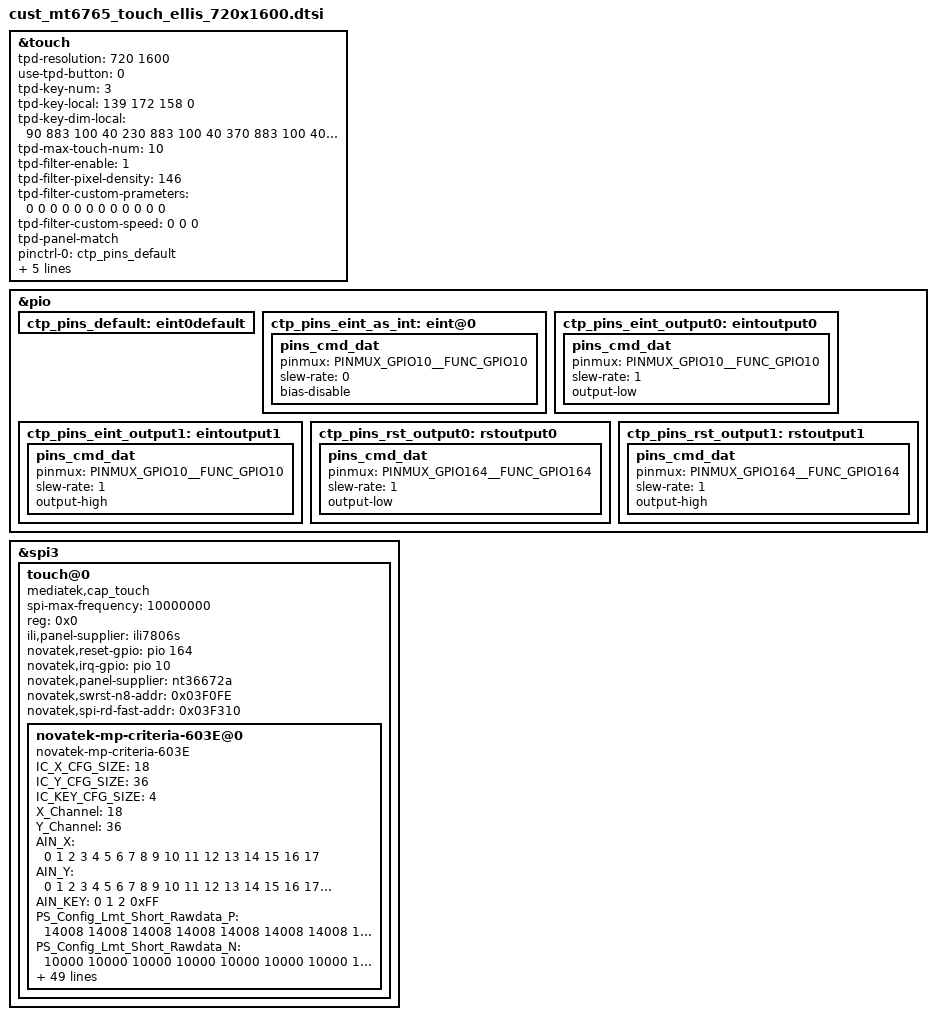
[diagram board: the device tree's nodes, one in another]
// SPDX-License-Identifier: GPL-2.0+
/*
 * Copyright (c) 2019 MediaTek Inc.
 *
 */

/* TOUCH start */
&touch {
	tpd-resolution = <720 1600>;
	use-tpd-button = <0>;
	tpd-key-num = <3>;
	tpd-key-local= <139 172 158 0>;
	tpd-key-dim-local = <90 883 100 40 230
				 883 100 40 370 883 100 40 0 0 0 0>;
	tpd-max-touch-num = <10>;
	tpd-filter-enable = <1>;
	tpd-filter-pixel-density = <146>;
	tpd-filter-custom-prameters = <0 0 0 0 0 0 0 0 0 0 0 0>;
	tpd-filter-custom-speed = <0 0 0>;
	tpd-panel-match;
	pinctrl-names = "default", "state_eint_as_int", "state_eint_output0",
		"state_eint_output1", "state_rst_output0", "state_rst_output1";
	pinctrl-0 = <&ctp_pins_default>;
	pinctrl-1 = <&ctp_pins_eint_as_int>;
	pinctrl-2 = <&ctp_pins_eint_output0>;
	pinctrl-3 = <&ctp_pins_eint_output1>;
	pinctrl-4 = <&ctp_pins_rst_output0>;
	pinctrl-5 = <&ctp_pins_rst_output1>;
	status = "okay";
};
&pio {
	ctp_pins_default: eint0default {
	};
	ctp_pins_eint_as_int: eint@0 {
		pins_cmd_dat {
			pinmux = <PINMUX_GPIO10__FUNC_GPIO10>;
			slew-rate = <0>;
			bias-disable;
		};
	};
	ctp_pins_eint_output0: eintoutput0 {
		pins_cmd_dat {
			pinmux = <PINMUX_GPIO10__FUNC_GPIO10>;
			slew-rate = <1>;
			output-low;
		};
	};
	ctp_pins_eint_output1: eintoutput1 {
		pins_cmd_dat {
			pinmux = <PINMUX_GPIO10__FUNC_GPIO10>;
			slew-rate = <1>;
			output-high;
		};
	};
	ctp_pins_rst_output0: rstoutput0 {
		pins_cmd_dat {
			pinmux = <PINMUX_GPIO164__FUNC_GPIO164>;
			slew-rate = <1>;
			output-low;
		};
	};
	ctp_pins_rst_output1: rstoutput1 {
		pins_cmd_dat {
			pinmux = <PINMUX_GPIO164__FUNC_GPIO164>;
			slew-rate = <1>;
			output-high;
		};
	};
};
/* TOUCH end */

&spi3 {
	#address-cells = <1>;
	#size-cells = <0>;

	touch@0{
		compatible = "mediatek,cap_touch","novatek,NVT-ts-spi";
 		spi-max-frequency = <10000000>;
		reg = <0x0>;
		status = "okay";

		ili,panel-supplier = "ili7806s";

		novatek,reset-gpio = <&pio 164 0>;
		novatek,irq-gpio = <&pio 10 2008>;
		novatek,panel-supplier = "nt36672a";

		//novatek,pen-support;
		//novatek,wgp-stylus;

		/* 525 */
		//novatek,swrst-n8-addr = <0x01F01A>;

		/* 672A, 525B, 675, 526, 672C, 523 */
		novatek,swrst-n8-addr = <0x03F0FE>;
		novatek,spi-rd-fast-addr = <0x03F310>;

		/* MP */
		//novatek,mp-support-dt;

		novatek-mp-criteria-603E@0 {
			#address-cells = <1>;
			#size-cells = <0>;
			compatible = "novatek-mp-criteria-603E";

			/* MP Config */
			IC_X_CFG_SIZE = <18>;
			IC_Y_CFG_SIZE = <36>;
			IC_KEY_CFG_SIZE = <4>;
			X_Channel = <18>;
			Y_Channel = <36>;
			AIN_X = <0 1 2 3 4 5 6 7 8 9 10 11 12 13 14 15 16 17>;
			AIN_Y = <0 1 2 3 4 5 6 7 8 9 10 11 12 13 14 15 16 17 18 19 20 21 22 23 24 25 26 27 28 29 30 31 32 33 34 35>;
			//AIN_X = <0 1 2 3 4 5 6 7 8 9 10 11 12 13 14 15 16 17 18 19 20 21 22 23 24 25 26 27 28 29 30 31>;
			//AIN_Y = <0 1 2 3 4 5 6 7 8 9 10 11 12 13 14 15 16 17 18 19 20 21 22 23 24 25 26 27 28 29 30 31 32 33 34 35 36 37 38 39 40 41 42 43 44 45 46 47 48 49>;
			AIN_KEY = <0 1 2 0xFF>;

			/* MP Criteria */
			PS_Config_Lmt_Short_Rawdata_P = <
				14008 14008 14008 14008 14008 14008 14008 14008 14008 14008 14008 14008 14008 14008 14008 14008 14008 14008 14008 14008 14008 14008 14008 14008 14008 14008 14008 14008 14008 14008 14008 14008
				14008 14008 14008 14008 14008 14008 14008 14008 14008 14008 14008 14008 14008 14008 14008 14008 14008 14008 14008 14008 14008 14008 14008 14008 14008 14008 14008 14008 14008 14008 14008 14008
				14008 14008 14008 14008 14008 14008 14008 14008 14008 14008 14008 14008 14008 14008 14008 14008 14008 14008 14008 14008 14008 14008 14008 14008 14008 14008 14008 14008 14008 14008 14008 14008
				14008 14008 14008 14008 14008 14008 14008 14008 14008 14008 14008 14008 14008 14008 14008 14008 14008 14008 14008 14008 14008 14008 14008 14008 14008 14008 14008 14008 14008 14008 14008 14008
				14008 14008 14008 14008 14008 14008 14008 14008 14008 14008 14008 14008 14008 14008 14008 14008 14008 14008 14008 14008 14008 14008 14008 14008 14008 14008 14008 14008 14008 14008 14008 14008
				14008 14008 14008 14008 14008 14008 14008 14008 14008 14008 14008 14008 14008 14008 14008 14008 14008 14008 14008 14008 14008 14008 14008 14008 14008 14008 14008 14008 14008 14008 14008 14008
				14008 14008 14008 14008 14008 14008 14008 14008 14008 14008 14008 14008 14008 14008 14008 14008 14008 14008 14008 14008 14008 14008 14008 14008 14008 14008 14008 14008 14008 14008 14008 14008
				14008 14008 14008 14008 14008 14008 14008 14008 14008 14008 14008 14008 14008 14008 14008 14008 14008 14008 14008 14008 14008 14008 14008 14008 14008 14008 14008 14008 14008 14008 14008 14008
				14008 14008 14008 14008 14008 14008 14008 14008 14008 14008 14008 14008 14008 14008 14008 14008 14008 14008 14008 14008 14008 14008 14008 14008 14008 14008 14008 14008 14008 14008 14008 14008
				14008 14008 14008 14008 14008 14008 14008 14008 14008 14008 14008 14008 14008 14008 14008 14008 14008 14008 14008 14008 14008 14008 14008 14008 14008 14008 14008 14008 14008 14008 14008 14008
				14008 14008 14008 14008 14008 14008 14008 14008 14008 14008 14008 14008 14008 14008 14008 14008 14008 14008 14008 14008 14008 14008 14008 14008 14008 14008 14008 14008 14008 14008 14008 14008
				14008 14008 14008 14008 14008 14008 14008 14008 14008 14008 14008 14008 14008 14008 14008 14008 14008 14008 14008 14008 14008 14008 14008 14008 14008 14008 14008 14008 14008 14008 14008 14008
				14008 14008 14008 14008 14008 14008 14008 14008 14008 14008 14008 14008 14008 14008 14008 14008 14008 14008 14008 14008 14008 14008 14008 14008 14008 14008 14008 14008 14008 14008 14008 14008
				14008 14008 14008 14008 14008 14008 14008 14008 14008 14008 14008 14008 14008 14008 14008 14008 14008 14008 14008 14008 14008 14008 14008 14008 14008 14008 14008 14008 14008 14008 14008 14008
				14008 14008 14008 14008 14008 14008 14008 14008 14008 14008 14008 14008 14008 14008 14008 14008 14008 14008 14008 14008 14008 14008 14008 14008 14008 14008 14008 14008 14008 14008 14008 14008
				14008 14008 14008 14008 14008 14008 14008 14008 14008 14008 14008 14008 14008 14008 14008 14008 14008 14008 14008 14008 14008 14008 14008 14008 14008 14008 14008 14008 14008 14008 14008 14008
				14008 14008 14008 14008 14008 14008 14008 14008 14008 14008 14008 14008 14008 14008 14008 14008 14008 14008 14008 14008 14008 14008 14008 14008 14008 14008 14008 14008 14008 14008 14008 14008
				14008 14008 14008 14008 14008 14008 14008 14008 14008 14008 14008 14008 14008 14008 14008 14008 14008 14008 14008 14008 14008 14008 14008 14008 14008 14008 14008 14008 14008 14008 14008 14008
				14008 14008 14008 14008 14008 14008 14008 14008 14008 14008 14008 14008 14008 14008 14008 14008 14008 14008 14008 14008 14008 14008 14008 14008 14008 14008 14008 14008 14008 14008 14008 14008
				14008 14008 14008 14008 14008 14008 14008 14008 14008 14008 14008 14008 14008 14008 14008 14008 14008 14008 14008 14008 14008 14008 14008 14008 14008 14008 14008 14008 14008 14008 14008 14008
				14008 14008 14008 14008 14008 14008 14008 14008 14008 14008 14008 14008 14008 14008 14008 14008 14008 14008 14008 14008 14008 14008 14008 14008 14008 14008 14008 14008 14008 14008 14008 14008
				14008 14008 14008 14008 14008 14008 14008 14008 14008 14008 14008 14008 14008 14008 14008 14008 14008 14008 14008 14008 14008 14008 14008 14008 14008 14008 14008 14008 14008 14008 14008 14008
				14008 14008 14008 14008 14008 14008 14008 14008 14008 14008 14008 14008 14008 14008 14008 14008 14008 14008 14008 14008 14008 14008 14008 14008 14008 14008 14008 14008 14008 14008 14008 14008
				14008 14008 14008 14008 14008 14008 14008 14008 14008 14008 14008 14008 14008 14008 14008 14008 14008 14008 14008 14008 14008 14008 14008 14008 14008 14008 14008 14008 14008 14008 14008 14008
				14008 14008 14008 14008 14008 14008 14008 14008 14008 14008 14008 14008 14008 14008 14008 14008 14008 14008 14008 14008 14008 14008 14008 14008 14008 14008 14008 14008 14008 14008 14008 14008
				14008 14008 14008 14008 14008 14008 14008 14008 14008 14008 14008 14008 14008 14008 14008 14008 14008 14008 14008 14008 14008 14008 14008 14008 14008 14008 14008 14008 14008 14008 14008 14008
				14008 14008 14008 14008 14008 14008 14008 14008 14008 14008 14008 14008 14008 14008 14008 14008 14008 14008 14008 14008 14008 14008 14008 14008 14008 14008 14008 14008 14008 14008 14008 14008
				14008 14008 14008 14008 14008 14008 14008 14008 14008 14008 14008 14008 14008 14008 14008 14008 14008 14008 14008 14008 14008 14008 14008 14008 14008 14008 14008 14008 14008 14008 14008 14008
				14008 14008 14008 14008 14008 14008 14008 14008 14008 14008 14008 14008 14008 14008 14008 14008 14008 14008 14008 14008 14008 14008 14008 14008 14008 14008 14008 14008 14008 14008 14008 14008
				14008 14008 14008 14008 14008 14008 14008 14008 14008 14008 14008 14008 14008 14008 14008 14008 14008 14008 14008 14008 14008 14008 14008 14008 14008 14008 14008 14008 14008 14008 14008 14008
				14008 14008 14008 14008 14008 14008 14008 14008 14008 14008 14008 14008 14008 14008 14008 14008 14008 14008 14008 14008 14008 14008 14008 14008 14008 14008 14008 14008 14008 14008 14008 14008
				14008 14008 14008 14008 14008 14008 14008 14008 14008 14008 14008 14008 14008 14008 14008 14008 14008 14008 14008 14008 14008 14008 14008 14008 14008 14008 14008 14008 14008 14008 14008 14008
				14008 14008 14008 14008 14008 14008 14008 14008 14008 14008 14008 14008 14008 14008 14008 14008 14008 14008 14008 14008 14008 14008 14008 14008 14008 14008 14008 14008 14008 14008 14008 14008
				14008 14008 14008 14008 14008 14008 14008 14008 14008 14008 14008 14008 14008 14008 14008 14008 14008 14008 14008 14008 14008 14008 14008 14008 14008 14008 14008 14008 14008 14008 14008 14008
				14008 14008 14008 14008 14008 14008 14008 14008 14008 14008 14008 14008 14008 14008 14008 14008 14008 14008 14008 14008 14008 14008 14008 14008 14008 14008 14008 14008 14008 14008 14008 14008
				14008 14008 14008 14008 14008 14008 14008 14008 14008 14008 14008 14008 14008 14008 14008 14008 14008 14008 14008 14008 14008 14008 14008 14008 14008 14008 14008 14008 14008 14008 14008 14008
				14008 14008 14008 14008 14008 14008 14008 14008 14008 14008 14008 14008 14008 14008 14008 14008 14008 14008 14008 14008 14008 14008 14008 14008 14008 14008 14008 14008 14008 14008 14008 14008
				14008 14008 14008 14008 14008 14008 14008 14008 14008 14008 14008 14008 14008 14008 14008 14008 14008 14008 14008 14008 14008 14008 14008 14008 14008 14008 14008 14008 14008 14008 14008 14008
				14008 14008 14008 14008 14008 14008 14008 14008 14008 14008 14008 14008 14008 14008 14008 14008 14008 14008 14008 14008 14008 14008 14008 14008 14008 14008 14008 14008 14008 14008 14008 14008
				14008 14008 14008 14008 14008 14008 14008 14008 14008 14008 14008 14008 14008 14008 14008 14008 14008 14008 14008 14008 14008 14008 14008 14008 14008 14008 14008 14008 14008 14008 14008 14008
				14008 14008 14008 14008 14008 14008 14008 14008 14008 14008 14008 14008 14008 14008 14008 14008 14008 14008 14008 14008 14008 14008 14008 14008 14008 14008 14008 14008 14008 14008 14008 14008
				14008 14008 14008 14008 14008 14008 14008 14008 14008 14008 14008 14008 14008 14008 14008 14008 14008 14008 14008 14008 14008 14008 14008 14008 14008 14008 14008 14008 14008 14008 14008 14008
				14008 14008 14008 14008 14008 14008 14008 14008 14008 14008 14008 14008 14008 14008 14008 14008 14008 14008 14008 14008 14008 14008 14008 14008 14008 14008 14008 14008 14008 14008 14008 14008
				14008 14008 14008 14008 14008 14008 14008 14008 14008 14008 14008 14008 14008 14008 14008 14008 14008 14008 14008 14008 14008 14008 14008 14008 14008 14008 14008 14008 14008 14008 14008 14008
				14008 14008 14008 14008 14008 14008 14008 14008 14008 14008 14008 14008 14008 14008 14008 14008 14008 14008 14008 14008 14008 14008 14008 14008 14008 14008 14008 14008 14008 14008 14008 14008
				14008 14008 14008 14008 14008 14008 14008 14008 14008 14008 14008 14008 14008 14008 14008 14008 14008 14008 14008 14008 14008 14008 14008 14008 14008 14008 14008 14008 14008 14008 14008 14008
				14008 14008 14008 14008 14008 14008 14008 14008 14008 14008 14008 14008 14008 14008 14008 14008 14008 14008 14008 14008 14008 14008 14008 14008 14008 14008 14008 14008 14008 14008 14008 14008
				14008 14008 14008 14008 14008 14008 14008 14008 14008 14008 14008 14008 14008 14008 14008 14008 14008 14008 14008 14008 14008 14008 14008 14008 14008 14008 14008 14008 14008 14008 14008 14008
				14008 14008 14008 14008 14008 14008 14008 14008 14008 14008 14008 14008 14008 14008 14008 14008 14008 14008 14008 14008 14008 14008 14008 14008 14008 14008 14008 14008 14008 14008 14008 14008
				14008 14008 14008 14008 14008 14008 14008 14008 14008 14008 14008 14008 14008 14008 14008 14008 14008 14008 14008 14008 14008 14008 14008 14008 14008 14008 14008 14008 14008 14008 14008 14008
				14008 14008 14008>;

			PS_Config_Lmt_Short_Rawdata_N = <
				10000 10000 10000 10000 10000 10000 10000 10000 10000 10000 10000 10000 10000 10000 10000 10000 10000 10000 10000 10000 10000 10000 10000 10000 10000 10000 10000 10000 10000 10000 10000 10000
				10000 10000 10000 10000 10000 10000 10000 10000 10000 10000 10000 10000 10000 10000 10000 10000 10000 10000 10000 10000 10000 10000 10000 10000 10000 10000 10000 10000 10000 10000 10000 10000
				10000 10000 10000 10000 10000 10000 10000 10000 10000 10000 10000 10000 10000 10000 10000 10000 10000 10000 10000 10000 10000 10000 10000 10000 10000 10000 10000 10000 10000 10000 10000 10000
				10000 10000 10000 10000 10000 10000 10000 10000 10000 10000 10000 10000 10000 10000 10000 10000 10000 10000 10000 10000 10000 10000 10000 10000 10000 10000 10000 10000 10000 10000 10000 10000
				10000 10000 10000 10000 10000 10000 10000 10000 10000 10000 10000 10000 10000 10000 10000 10000 10000 10000 10000 10000 10000 10000 10000 10000 10000 10000 10000 10000 10000 10000 10000 10000
				10000 10000 10000 10000 10000 10000 10000 10000 10000 10000 10000 10000 10000 10000 10000 10000 10000 10000 10000 10000 10000 10000 10000 10000 10000 10000 10000 10000 10000 10000 10000 10000
				10000 10000 10000 10000 10000 10000 10000 10000 10000 10000 10000 10000 10000 10000 10000 10000 10000 10000 10000 10000 10000 10000 10000 10000 10000 10000 10000 10000 10000 10000 10000 10000
				10000 10000 10000 10000 10000 10000 10000 10000 10000 10000 10000 10000 10000 10000 10000 10000 10000 10000 10000 10000 10000 10000 10000 10000 10000 10000 10000 10000 10000 10000 10000 10000
				10000 10000 10000 10000 10000 10000 10000 10000 10000 10000 10000 10000 10000 10000 10000 10000 10000 10000 10000 10000 10000 10000 10000 10000 10000 10000 10000 10000 10000 10000 10000 10000
				10000 10000 10000 10000 10000 10000 10000 10000 10000 10000 10000 10000 10000 10000 10000 10000 10000 10000 10000 10000 10000 10000 10000 10000 10000 10000 10000 10000 10000 10000 10000 10000
				10000 10000 10000 10000 10000 10000 10000 10000 10000 10000 10000 10000 10000 10000 10000 10000 10000 10000 10000 10000 10000 10000 10000 10000 10000 10000 10000 10000 10000 10000 10000 10000
				10000 10000 10000 10000 10000 10000 10000 10000 10000 10000 10000 10000 10000 10000 10000 10000 10000 10000 10000 10000 10000 10000 10000 10000 10000 10000 10000 10000 10000 10000 10000 10000
				10000 10000 10000 10000 10000 10000 10000 10000 10000 10000 10000 10000 10000 10000 10000 10000 10000 10000 10000 10000 10000 10000 10000 10000 10000 10000 10000 10000 10000 10000 10000 10000
				10000 10000 10000 10000 10000 10000 10000 10000 10000 10000 10000 10000 10000 10000 10000 10000 10000 10000 10000 10000 10000 10000 10000 10000 10000 10000 10000 10000 10000 10000 10000 10000
				10000 10000 10000 10000 10000 10000 10000 10000 10000 10000 10000 10000 10000 10000 10000 10000 10000 10000 10000 10000 10000 10000 10000 10000 10000 10000 10000 10000 10000 10000 10000 10000
				10000 10000 10000 10000 10000 10000 10000 10000 10000 10000 10000 10000 10000 10000 10000 10000 10000 10000 10000 10000 10000 10000 10000 10000 10000 10000 10000 10000 10000 10000 10000 10000
				10000 10000 10000 10000 10000 10000 10000 10000 10000 10000 10000 10000 10000 10000 10000 10000 10000 10000 10000 10000 10000 10000 10000 10000 10000 10000 10000 10000 10000 10000 10000 10000
				10000 10000 10000 10000 10000 10000 10000 10000 10000 10000 10000 10000 10000 10000 10000 10000 10000 10000 10000 10000 10000 10000 10000 10000 10000 10000 10000 10000 10000 10000 10000 10000
				10000 10000 10000 10000 10000 10000 10000 10000 10000 10000 10000 10000 10000 10000 10000 10000 10000 10000 10000 10000 10000 10000 10000 10000 10000 10000 10000 10000 10000 10000 10000 10000
				10000 10000 10000 10000 10000 10000 10000 10000 10000 10000 10000 10000 10000 10000 10000 10000 10000 10000 10000 10000 10000 10000 10000 10000 10000 10000 10000 10000 10000 10000 10000 10000
				10000 10000 10000 10000 10000 10000 10000 10000 10000 10000 10000 10000 10000 10000 10000 10000 10000 10000 10000 10000 10000 10000 10000 10000 10000 10000 10000 10000 10000 10000 10000 10000
				10000 10000 10000 10000 10000 10000 10000 10000 10000 10000 10000 10000 10000 10000 10000 10000 10000 10000 10000 10000 10000 10000 10000 10000 10000 10000 10000 10000 10000 10000 10000 10000
				10000 10000 10000 10000 10000 10000 10000 10000 10000 10000 10000 10000 10000 10000 10000 10000 10000 10000 10000 10000 10000 10000 10000 10000 10000 10000 10000 10000 10000 10000 10000 10000
				10000 10000 10000 10000 10000 10000 10000 10000 10000 10000 10000 10000 10000 10000 10000 10000 10000 10000 10000 10000 10000 10000 10000 10000 10000 10000 10000 10000 10000 10000 10000 10000
				10000 10000 10000 10000 10000 10000 10000 10000 10000 10000 10000 10000 10000 10000 10000 10000 10000 10000 10000 10000 10000 10000 10000 10000 10000 10000 10000 10000 10000 10000 10000 10000
				10000 10000 10000 10000 10000 10000 10000 10000 10000 10000 10000 10000 10000 10000 10000 10000 10000 10000 10000 10000 10000 10000 10000 10000 10000 10000 10000 10000 10000 10000 10000 10000
				10000 10000 10000 10000 10000 10000 10000 10000 10000 10000 10000 10000 10000 10000 10000 10000 10000 10000 10000 10000 10000 10000 10000 10000 10000 10000 10000 10000 10000 10000 10000 10000
				10000 10000 10000 10000 10000 10000 10000 10000 10000 10000 10000 10000 10000 10000 10000 10000 10000 10000 10000 10000 10000 10000 10000 10000 10000 10000 10000 10000 10000 10000 10000 10000
				10000 10000 10000 10000 10000 10000 10000 10000 10000 10000 10000 10000 10000 10000 10000 10000 10000 10000 10000 10000 10000 10000 10000 10000 10000 10000 10000 10000 10000 10000 10000 10000
				10000 10000 10000 10000 10000 10000 10000 10000 10000 10000 10000 10000 10000 10000 10000 10000 10000 10000 10000 10000 10000 10000 10000 10000 10000 10000 10000 10000 10000 10000 10000 10000
				10000 10000 10000 10000 10000 10000 10000 10000 10000 10000 10000 10000 10000 10000 10000 10000 10000 10000 10000 10000 10000 10000 10000 10000 10000 10000 10000 10000 10000 10000 10000 10000
				10000 10000 10000 10000 10000 10000 10000 10000 10000 10000 10000 10000 10000 10000 10000 10000 10000 10000 10000 10000 10000 10000 10000 10000 10000 10000 10000 10000 10000 10000 10000 10000
				10000 10000 10000 10000 10000 10000 10000 10000 10000 10000 10000 10000 10000 10000 10000 10000 10000 10000 10000 10000 10000 10000 10000 10000 10000 10000 10000 10000 10000 10000 10000 10000
				10000 10000 10000 10000 10000 10000 10000 10000 10000 10000 10000 10000 10000 10000 10000 10000 10000 10000 10000 10000 10000 10000 10000 10000 10000 10000 10000 10000 10000 10000 10000 10000
				10000 10000 10000 10000 10000 10000 10000 10000 10000 10000 10000 10000 10000 10000 10000 10000 10000 10000 10000 10000 10000 10000 10000 10000 10000 10000 10000 10000 10000 10000 10000 10000
				10000 10000 10000 10000 10000 10000 10000 10000 10000 10000 10000 10000 10000 10000 10000 10000 10000 10000 10000 10000 10000 10000 10000 10000 10000 10000 10000 10000 10000 10000 10000 10000
				10000 10000 10000 10000 10000 10000 10000 10000 10000 10000 10000 10000 10000 10000 10000 10000 10000 10000 10000 10000 10000 10000 10000 10000 10000 10000 10000 10000 10000 10000 10000 10000
				10000 10000 10000 10000 10000 10000 10000 10000 10000 10000 10000 10000 10000 10000 10000 10000 10000 10000 10000 10000 10000 10000 10000 10000 10000 10000 10000 10000 10000 10000 10000 10000
				10000 10000 10000 10000 10000 10000 10000 10000 10000 10000 10000 10000 10000 10000 10000 10000 10000 10000 10000 10000 10000 10000 10000 10000 10000 10000 10000 10000 10000 10000 10000 10000
				10000 10000 10000 10000 10000 10000 10000 10000 10000 10000 10000 10000 10000 10000 10000 10000 10000 10000 10000 10000 10000 10000 10000 10000 10000 10000 10000 10000 10000 10000 10000 10000
				10000 10000 10000 10000 10000 10000 10000 10000 10000 10000 10000 10000 10000 10000 10000 10000 10000 10000 10000 10000 10000 10000 10000 10000 10000 10000 10000 10000 10000 10000 10000 10000
				10000 10000 10000 10000 10000 10000 10000 10000 10000 10000 10000 10000 10000 10000 10000 10000 10000 10000 10000 10000 10000 10000 10000 10000 10000 10000 10000 10000 10000 10000 10000 10000
				10000 10000 10000 10000 10000 10000 10000 10000 10000 10000 10000 10000 10000 10000 10000 10000 10000 10000 10000 10000 10000 10000 10000 10000 10000 10000 10000 10000 10000 10000 10000 10000
				10000 10000 10000 10000 10000 10000 10000 10000 10000 10000 10000 10000 10000 10000 10000 10000 10000 10000 10000 10000 10000 10000 10000 10000 10000 10000 10000 10000 10000 10000 10000 10000
				10000 10000 10000 10000 10000 10000 10000 10000 10000 10000 10000 10000 10000 10000 10000 10000 10000 10000 10000 10000 10000 10000 10000 10000 10000 10000 10000 10000 10000 10000 10000 10000
				10000 10000 10000 10000 10000 10000 10000 10000 10000 10000 10000 10000 10000 10000 10000 10000 10000 10000 10000 10000 10000 10000 10000 10000 10000 10000 10000 10000 10000 10000 10000 10000
				10000 10000 10000 10000 10000 10000 10000 10000 10000 10000 10000 10000 10000 10000 10000 10000 10000 10000 10000 10000 10000 10000 10000 10000 10000 10000 10000 10000 10000 10000 10000 10000
				10000 10000 10000 10000 10000 10000 10000 10000 10000 10000 10000 10000 10000 10000 10000 10000 10000 10000 10000 10000 10000 10000 10000 10000 10000 10000 10000 10000 10000 10000 10000 10000
				10000 10000 10000 10000 10000 10000 10000 10000 10000 10000 10000 10000 10000 10000 10000 10000 10000 10000 10000 10000 10000 10000 10000 10000 10000 10000 10000 10000 10000 10000 10000 10000
				10000 10000 10000 10000 10000 10000 10000 10000 10000 10000 10000 10000 10000 10000 10000 10000 10000 10000 10000 10000 10000 10000 10000 10000 10000 10000 10000 10000 10000 10000 10000 10000
				10000 10000 10000>;

			PS_Config_Lmt_Open_Rawdata_P = <
				5120 5120 5120 5120 5120 5120 5120 5120 5120 5120 5120 5120 5120 5120 5120 5120 5120 5120 5120 5120 5120 5120 5120 5120 5120 5120 5120 5120 5120 5120 5120 5120
				5120 5120 5120 5120 5120 5120 5120 5120 5120 5120 5120 5120 5120 5120 5120 5120 5120 5120 5120 5120 5120 5120 5120 5120 5120 5120 5120 5120 5120 5120 5120 5120
				5120 5120 5120 5120 5120 5120 5120 5120 5120 5120 5120 5120 5120 5120 5120 5120 5120 5120 5120 5120 5120 5120 5120 5120 5120 5120 5120 5120 5120 5120 5120 5120
				5120 5120 5120 5120 5120 5120 5120 5120 5120 5120 5120 5120 5120 5120 5120 5120 5120 5120 5120 5120 5120 5120 5120 5120 5120 5120 5120 5120 5120 5120 5120 5120
				5120 5120 5120 5120 5120 5120 5120 5120 5120 5120 5120 5120 5120 5120 5120 5120 5120 5120 5120 5120 5120 5120 5120 5120 5120 5120 5120 5120 5120 5120 5120 5120
				5120 5120 5120 5120 5120 5120 5120 5120 5120 5120 5120 5120 5120 5120 5120 5120 5120 5120 5120 5120 5120 5120 5120 5120 5120 5120 5120 5120 5120 5120 5120 5120
				5120 5120 5120 5120 5120 5120 5120 5120 5120 5120 5120 5120 5120 5120 5120 5120 5120 5120 5120 5120 5120 5120 5120 5120 5120 5120 5120 5120 5120 5120 5120 5120
				5120 5120 5120 5120 5120 5120 5120 5120 5120 5120 5120 5120 5120 5120 5120 5120 5120 5120 5120 5120 5120 5120 5120 5120 5120 5120 5120 5120 5120 5120 5120 5120
				5120 5120 5120 5120 5120 5120 5120 5120 5120 5120 5120 5120 5120 5120 5120 5120 5120 5120 5120 5120 5120 5120 5120 5120 5120 5120 5120 5120 5120 5120 5120 5120
				5120 5120 5120 5120 5120 5120 5120 5120 5120 5120 5120 5120 5120 5120 5120 5120 5120 5120 5120 5120 5120 5120 5120 5120 5120 5120 5120 5120 5120 5120 5120 5120
				5120 5120 5120 5120 5120 5120 5120 5120 5120 5120 5120 5120 5120 5120 5120 5120 5120 5120 5120 5120 5120 5120 5120 5120 5120 5120 5120 5120 5120 5120 5120 5120
				5120 5120 5120 5120 5120 5120 5120 5120 5120 5120 5120 5120 5120 5120 5120 5120 5120 5120 5120 5120 5120 5120 5120 5120 5120 5120 5120 5120 5120 5120 5120 5120
				5120 5120 5120 5120 5120 5120 5120 5120 5120 5120 5120 5120 5120 5120 5120 5120 5120 5120 5120 5120 5120 5120 5120 5120 5120 5120 5120 5120 5120 5120 5120 5120
				5120 5120 5120 5120 5120 5120 5120 5120 5120 5120 5120 5120 5120 5120 5120 5120 5120 5120 5120 5120 5120 5120 5120 5120 5120 5120 5120 5120 5120 5120 5120 5120
				5120 5120 5120 5120 5120 5120 5120 5120 5120 5120 5120 5120 5120 5120 5120 5120 5120 5120 5120 5120 5120 5120 5120 5120 5120 5120 5120 5120 5120 5120 5120 5120
				5120 5120 5120 5120 5120 5120 5120 5120 5120 5120 5120 5120 5120 5120 5120 5120 5120 5120 5120 5120 5120 5120 5120 5120 5120 5120 5120 5120 5120 5120 5120 5120
				5120 5120 5120 5120 5120 5120 5120 5120 5120 5120 5120 5120 5120 5120 5120 5120 5120 5120 5120 5120 5120 5120 5120 5120 5120 5120 5120 5120 5120 5120 5120 5120
				5120 5120 5120 5120 5120 5120 5120 5120 5120 5120 5120 5120 5120 5120 5120 5120 5120 5120 5120 5120 5120 5120 5120 5120 5120 5120 5120 5120 5120 5120 5120 5120
				5120 5120 5120 5120 5120 5120 5120 5120 5120 5120 5120 5120 5120 5120 5120 5120 5120 5120 5120 5120 5120 5120 5120 5120 5120 5120 5120 5120 5120 5120 5120 5120
				5120 5120 5120 5120 5120 5120 5120 5120 5120 5120 5120 5120 5120 5120 5120 5120 5120 5120 5120 5120 5120 5120 5120 5120 5120 5120 5120 5120 5120 5120 5120 5120
				5120 5120 5120 5120 5120 5120 5120 5120 5120 5120 5120 5120 5120 5120 5120 5120 5120 5120 5120 5120 5120 5120 5120 5120 5120 5120 5120 5120 5120 5120 5120 5120
				5120 5120 5120 5120 5120 5120 5120 5120 5120 5120 5120 5120 5120 5120 5120 5120 5120 5120 5120 5120 5120 5120 5120 5120 5120 5120 5120 5120 5120 5120 5120 5120
				5120 5120 5120 5120 5120 5120 5120 5120 5120 5120 5120 5120 5120 5120 5120 5120 5120 5120 5120 5120 5120 5120 5120 5120 5120 5120 5120 5120 5120 5120 5120 5120
				5120 5120 5120 5120 5120 5120 5120 5120 5120 5120 5120 5120 5120 5120 5120 5120 5120 5120 5120 5120 5120 5120 5120 5120 5120 5120 5120 5120 5120 5120 5120 5120
				5120 5120 5120 5120 5120 5120 5120 5120 5120 5120 5120 5120 5120 5120 5120 5120 5120 5120 5120 5120 5120 5120 5120 5120 5120 5120 5120 5120 5120 5120 5120 5120
				5120 5120 5120 5120 5120 5120 5120 5120 5120 5120 5120 5120 5120 5120 5120 5120 5120 5120 5120 5120 5120 5120 5120 5120 5120 5120 5120 5120 5120 5120 5120 5120
				5120 5120 5120 5120 5120 5120 5120 5120 5120 5120 5120 5120 5120 5120 5120 5120 5120 5120 5120 5120 5120 5120 5120 5120 5120 5120 5120 5120 5120 5120 5120 5120
				5120 5120 5120 5120 5120 5120 5120 5120 5120 5120 5120 5120 5120 5120 5120 5120 5120 5120 5120 5120 5120 5120 5120 5120 5120 5120 5120 5120 5120 5120 5120 5120
				5120 5120 5120 5120 5120 5120 5120 5120 5120 5120 5120 5120 5120 5120 5120 5120 5120 5120 5120 5120 5120 5120 5120 5120 5120 5120 5120 5120 5120 5120 5120 5120
				5120 5120 5120 5120 5120 5120 5120 5120 5120 5120 5120 5120 5120 5120 5120 5120 5120 5120 5120 5120 5120 5120 5120 5120 5120 5120 5120 5120 5120 5120 5120 5120
				5120 5120 5120 5120 5120 5120 5120 5120 5120 5120 5120 5120 5120 5120 5120 5120 5120 5120 5120 5120 5120 5120 5120 5120 5120 5120 5120 5120 5120 5120 5120 5120
				5120 5120 5120 5120 5120 5120 5120 5120 5120 5120 5120 5120 5120 5120 5120 5120 5120 5120 5120 5120 5120 5120 5120 5120 5120 5120 5120 5120 5120 5120 5120 5120
				5120 5120 5120 5120 5120 5120 5120 5120 5120 5120 5120 5120 5120 5120 5120 5120 5120 5120 5120 5120 5120 5120 5120 5120 5120 5120 5120 5120 5120 5120 5120 5120
				5120 5120 5120 5120 5120 5120 5120 5120 5120 5120 5120 5120 5120 5120 5120 5120 5120 5120 5120 5120 5120 5120 5120 5120 5120 5120 5120 5120 5120 5120 5120 5120
				5120 5120 5120 5120 5120 5120 5120 5120 5120 5120 5120 5120 5120 5120 5120 5120 5120 5120 5120 5120 5120 5120 5120 5120 5120 5120 5120 5120 5120 5120 5120 5120
				5120 5120 5120 5120 5120 5120 5120 5120 5120 5120 5120 5120 5120 5120 5120 5120 5120 5120 5120 5120 5120 5120 5120 5120 5120 5120 5120 5120 5120 5120 5120 5120
				5120 5120 5120 5120 5120 5120 5120 5120 5120 5120 5120 5120 5120 5120 5120 5120 5120 5120 5120 5120 5120 5120 5120 5120 5120 5120 5120 5120 5120 5120 5120 5120
				5120 5120 5120 5120 5120 5120 5120 5120 5120 5120 5120 5120 5120 5120 5120 5120 5120 5120 5120 5120 5120 5120 5120 5120 5120 5120 5120 5120 5120 5120 5120 5120
				5120 5120 5120 5120 5120 5120 5120 5120 5120 5120 5120 5120 5120 5120 5120 5120 5120 5120 5120 5120 5120 5120 5120 5120 5120 5120 5120 5120 5120 5120 5120 5120
				5120 5120 5120 5120 5120 5120 5120 5120 5120 5120 5120 5120 5120 5120 5120 5120 5120 5120 5120 5120 5120 5120 5120 5120 5120 5120 5120 5120 5120 5120 5120 5120
				5120 5120 5120 5120 5120 5120 5120 5120 5120 5120 5120 5120 5120 5120 5120 5120 5120 5120 5120 5120 5120 5120 5120 5120 5120 5120 5120 5120 5120 5120 5120 5120
				5120 5120 5120 5120 5120 5120 5120 5120 5120 5120 5120 5120 5120 5120 5120 5120 5120 5120 5120 5120 5120 5120 5120 5120 5120 5120 5120 5120 5120 5120 5120 5120
				5120 5120 5120 5120 5120 5120 5120 5120 5120 5120 5120 5120 5120 5120 5120 5120 5120 5120 5120 5120 5120 5120 5120 5120 5120 5120 5120 5120 5120 5120 5120 5120
				5120 5120 5120 5120 5120 5120 5120 5120 5120 5120 5120 5120 5120 5120 5120 5120 5120 5120 5120 5120 5120 5120 5120 5120 5120 5120 5120 5120 5120 5120 5120 5120
				5120 5120 5120 5120 5120 5120 5120 5120 5120 5120 5120 5120 5120 5120 5120 5120 5120 5120 5120 5120 5120 5120 5120 5120 5120 5120 5120 5120 5120 5120 5120 5120
				5120 5120 5120 5120 5120 5120 5120 5120 5120 5120 5120 5120 5120 5120 5120 5120 5120 5120 5120 5120 5120 5120 5120 5120 5120 5120 5120 5120 5120 5120 5120 5120
				5120 5120 5120 5120 5120 5120 5120 5120 5120 5120 5120 5120 5120 5120 5120 5120 5120 5120 5120 5120 5120 5120 5120 5120 5120 5120 5120 5120 5120 5120 5120 5120
				5120 5120 5120 5120 5120 5120 5120 5120 5120 5120 5120 5120 5120 5120 5120 5120 5120 5120 5120 5120 5120 5120 5120 5120 5120 5120 5120 5120 5120 5120 5120 5120
				5120 5120 5120 5120 5120 5120 5120 5120 5120 5120 5120 5120 5120 5120 5120 5120 5120 5120 5120 5120 5120 5120 5120 5120 5120 5120 5120 5120 5120 5120 5120 5120
				5120 5120 5120 5120 5120 5120 5120 5120 5120 5120 5120 5120 5120 5120 5120 5120 5120 5120 5120 5120 5120 5120 5120 5120 5120 5120 5120 5120 5120 5120 5120 5120
				5120 5120 5120>;

			PS_Config_Lmt_Open_Rawdata_N = <
				(-511) (-511) (-511) (-511) (-511) (-511) (-511) (-511) (-511) (-511) (-511) (-511) (-511) (-511) (-511) (-511) (-511) (-511) (-511) (-511) (-511) (-511) (-511) (-511) (-511) (-511) (-511) (-511) (-511) (-511) (-511) (-511)
				(-511) (-511) (-511) (-511) (-511) (-511) (-511) (-511) (-511) (-511) (-511) (-511) (-511) (-511) (-511) (-511) (-511) (-511) (-511) (-511) (-511) (-511) (-511) (-511) (-511) (-511) (-511) (-511) (-511) (-511) (-511) (-511)
				(-511) (-511) (-511) (-511) (-511) (-511) (-511) (-511) (-511) (-511) (-511) (-511) (-511) (-511) (-511) (-511) (-511) (-511) (-511) (-511) (-511) (-511) (-511) (-511) (-511) (-511) (-511) (-511) (-511) (-511) (-511) (-511)
				(-511) (-511) (-511) (-511) (-511) (-511) (-511) (-511) (-511) (-511) (-511) (-511) (-511) (-511) (-511) (-511) (-511) (-511) (-511) (-511) (-511) (-511) (-511) (-511) (-511) (-511) (-511) (-511) (-511) (-511) (-511) (-511)
				(-511) (-511) (-511) (-511) (-511) (-511) (-511) (-511) (-511) (-511) (-511) (-511) (-511) (-511) (-511) (-511) (-511) (-511) (-511) (-511) (-511) (-511) (-511) (-511) (-511) (-511) (-511) (-511) (-511) (-511) (-511) (-511)
				(-511) (-511) (-511) (-511) (-511) (-511) (-511) (-511) (-511) (-511) (-511) (-511) (-511) (-511) (-511) (-511) (-511) (-511) (-511) (-511) (-511) (-511) (-511) (-511) (-511) (-511) (-511) (-511) (-511) (-511) (-511) (-511)
				(-511) (-511) (-511) (-511) (-511) (-511) (-511) (-511) (-511) (-511) (-511) (-511) (-511) (-511) (-511) (-511) (-511) (-511) (-511) (-511) (-511) (-511) (-511) (-511) (-511) (-511) (-511) (-511) (-511) (-511) (-511) (-511)
				(-511) (-511) (-511) (-511) (-511) (-511) (-511) (-511) (-511) (-511) (-511) (-511) (-511) (-511) (-511) (-511) (-511) (-511) (-511) (-511) (-511) (-511) (-511) (-511) (-511) (-511) (-511) (-511) (-511) (-511) (-511) (-511)
				(-511) (-511) (-511) (-511) (-511) (-511) (-511) (-511) (-511) (-511) (-511) (-511) (-511) (-511) (-511) (-511) (-511) (-511) (-511) (-511) (-511) (-511) (-511) (-511) (-511) (-511) (-511) (-511) (-511) (-511) (-511) (-511)
				(-511) (-511) (-511) (-511) (-511) (-511) (-511) (-511) (-511) (-511) (-511) (-511) (-511) (-511) (-511) (-511) (-511) (-511) (-511) (-511) (-511) (-511) (-511) (-511) (-511) (-511) (-511) (-511) (-511) (-511) (-511) (-511)
				(-511) (-511) (-511) (-511) (-511) (-511) (-511) (-511) (-511) (-511) (-511) (-511) (-511) (-511) (-511) (-511) (-511) (-511) (-511) (-511) (-511) (-511) (-511) (-511) (-511) (-511) (-511) (-511) (-511) (-511) (-511) (-511)
				(-511) (-511) (-511) (-511) (-511) (-511) (-511) (-511) (-511) (-511) (-511) (-511) (-511) (-511) (-511) (-511) (-511) (-511) (-511) (-511) (-511) (-511) (-511) (-511) (-511) (-511) (-511) (-511) (-511) (-511) (-511) (-511)
				(-511) (-511) (-511) (-511) (-511) (-511) (-511) (-511) (-511) (-511) (-511) (-511) (-511) (-511) (-511) (-511) (-511) (-511) (-511) (-511) (-511) (-511) (-511) (-511) (-511) (-511) (-511) (-511) (-511) (-511) (-511) (-511)
				(-511) (-511) (-511) (-511) (-511) (-511) (-511) (-511) (-511) (-511) (-511) (-511) (-511) (-511) (-511) (-511) (-511) (-511) (-511) (-511) (-511) (-511) (-511) (-511) (-511) (-511) (-511) (-511) (-511) (-511) (-511) (-511)
				(-511) (-511) (-511) (-511) (-511) (-511) (-511) (-511) (-511) (-511) (-511) (-511) (-511) (-511) (-511) (-511) (-511) (-511) (-511) (-511) (-511) (-511) (-511) (-511) (-511) (-511) (-511) (-511) (-511) (-511) (-511) (-511)
				(-511) (-511) (-511) (-511) (-511) (-511) (-511) (-511) (-511) (-511) (-511) (-511) (-511) (-511) (-511) (-511) (-511) (-511) (-511) (-511) (-511) (-511) (-511) (-511) (-511) (-511) (-511) (-511) (-511) (-511) (-511) (-511)
				(-511) (-511) (-511) (-511) (-511) (-511) (-511) (-511) (-511) (-511) (-511) (-511) (-511) (-511) (-511) (-511) (-511) (-511) (-511) (-511) (-511) (-511) (-511) (-511) (-511) (-511) (-511) (-511) (-511) (-511) (-511) (-511)
				(-511) (-511) (-511) (-511) (-511) (-511) (-511) (-511) (-511) (-511) (-511) (-511) (-511) (-511) (-511) (-511) (-511) (-511) (-511) (-511) (-511) (-511) (-511) (-511) (-511) (-511) (-511) (-511) (-511) (-511) (-511) (-511)
				(-511) (-511) (-511) (-511) (-511) (-511) (-511) (-511) (-511) (-511) (-511) (-511) (-511) (-511) (-511) (-511) (-511) (-511) (-511) (-511) (-511) (-511) (-511) (-511) (-511) (-511) (-511) (-511) (-511) (-511) (-511) (-511)
				(-511) (-511) (-511) (-511) (-511) (-511) (-511) (-511) (-511) (-511) (-511) (-511) (-511) (-511) (-511) (-511) (-511) (-511) (-511) (-511) (-511) (-511) (-511) (-511) (-511) (-511) (-511) (-511) (-511) (-511) (-511) (-511)
				(-511) (-511) (-511) (-511) (-511) (-511) (-511) (-511) (-511) (-511) (-511) (-511) (-511) (-511) (-511) (-511) (-511) (-511) (-511) (-511) (-511) (-511) (-511) (-511) (-511) (-511) (-511) (-511) (-511) (-511) (-511) (-511)
				(-511) (-511) (-511) (-511) (-511) (-511) (-511) (-511) (-511) (-511) (-511) (-511) (-511) (-511) (-511) (-511) (-511) (-511) (-511) (-511) (-511) (-511) (-511) (-511) (-511) (-511) (-511) (-511) (-511) (-511) (-511) (-511)
				(-511) (-511) (-511) (-511) (-511) (-511) (-511) (-511) (-511) (-511) (-511) (-511) (-511) (-511) (-511) (-511) (-511) (-511) (-511) (-511) (-511) (-511) (-511) (-511) (-511) (-511) (-511) (-511) (-511) (-511) (-511) (-511)
				(-511) (-511) (-511) (-511) (-511) (-511) (-511) (-511) (-511) (-511) (-511) (-511) (-511) (-511) (-511) (-511) (-511) (-511) (-511) (-511) (-511) (-511) (-511) (-511) (-511) (-511) (-511) (-511) (-511) (-511) (-511) (-511)
				(-511) (-511) (-511) (-511) (-511) (-511) (-511) (-511) (-511) (-511) (-511) (-511) (-511) (-511) (-511) (-511) (-511) (-511) (-511) (-511) (-511) (-511) (-511) (-511) (-511) (-511) (-511) (-511) (-511) (-511) (-511) (-511)
				(-511) (-511) (-511) (-511) (-511) (-511) (-511) (-511) (-511) (-511) (-511) (-511) (-511) (-511) (-511) (-511) (-511) (-511) (-511) (-511) (-511) (-511) (-511) (-511) (-511) (-511) (-511) (-511) (-511) (-511) (-511) (-511)
				(-511) (-511) (-511) (-511) (-511) (-511) (-511) (-511) (-511) (-511) (-511) (-511) (-511) (-511) (-511) (-511) (-511) (-511) (-511) (-511) (-511) (-511) (-511) (-511) (-511) (-511) (-511) (-511) (-511) (-511) (-511) (-511)
				(-511) (-511) (-511) (-511) (-511) (-511) (-511) (-511) (-511) (-511) (-511) (-511) (-511) (-511) (-511) (-511) (-511) (-511) (-511) (-511) (-511) (-511) (-511) (-511) (-511) (-511) (-511) (-511) (-511) (-511) (-511) (-511)
				(-511) (-511) (-511) (-511) (-511) (-511) (-511) (-511) (-511) (-511) (-511) (-511) (-511) (-511) (-511) (-511) (-511) (-511) (-511) (-511) (-511) (-511) (-511) (-511) (-511) (-511) (-511) (-511) (-511) (-511) (-511) (-511)
				(-511) (-511) (-511) (-511) (-511) (-511) (-511) (-511) (-511) (-511) (-511) (-511) (-511) (-511) (-511) (-511) (-511) (-511) (-511) (-511) (-511) (-511) (-511) (-511) (-511) (-511) (-511) (-511) (-511) (-511) (-511) (-511)
				(-511) (-511) (-511) (-511) (-511) (-511) (-511) (-511) (-511) (-511) (-511) (-511) (-511) (-511) (-511) (-511) (-511) (-511) (-511) (-511) (-511) (-511) (-511) (-511) (-511) (-511) (-511) (-511) (-511) (-511) (-511) (-511)
				(-511) (-511) (-511) (-511) (-511) (-511) (-511) (-511) (-511) (-511) (-511) (-511) (-511) (-511) (-511) (-511) (-511) (-511) (-511) (-511) (-511) (-511) (-511) (-511) (-511) (-511) (-511) (-511) (-511) (-511) (-511) (-511)
				(-511) (-511) (-511) (-511) (-511) (-511) (-511) (-511) (-511) (-511) (-511) (-511) (-511) (-511) (-511) (-511) (-511) (-511) (-511) (-511) (-511) (-511) (-511) (-511) (-511) (-511) (-511) (-511) (-511) (-511) (-511) (-511)
				(-511) (-511) (-511) (-511) (-511) (-511) (-511) (-511) (-511) (-511) (-511) (-511) (-511) (-511) (-511) (-511) (-511) (-511) (-511) (-511) (-511) (-511) (-511) (-511) (-511) (-511) (-511) (-511) (-511) (-511) (-511) (-511)
				(-511) (-511) (-511) (-511) (-511) (-511) (-511) (-511) (-511) (-511) (-511) (-511) (-511) (-511) (-511) (-511) (-511) (-511) (-511) (-511) (-511) (-511) (-511) (-511) (-511) (-511) (-511) (-511) (-511) (-511) (-511) (-511)
				(-511) (-511) (-511) (-511) (-511) (-511) (-511) (-511) (-511) (-511) (-511) (-511) (-511) (-511) (-511) (-511) (-511) (-511) (-511) (-511) (-511) (-511) (-511) (-511) (-511) (-511) (-511) (-511) (-511) (-511) (-511) (-511)
				(-511) (-511) (-511) (-511) (-511) (-511) (-511) (-511) (-511) (-511) (-511) (-511) (-511) (-511) (-511) (-511) (-511) (-511) (-511) (-511) (-511) (-511) (-511) (-511) (-511) (-511) (-511) (-511) (-511) (-511) (-511) (-511)
				(-511) (-511) (-511) (-511) (-511) (-511) (-511) (-511) (-511) (-511) (-511) (-511) (-511) (-511) (-511) (-511) (-511) (-511) (-511) (-511) (-511) (-511) (-511) (-511) (-511) (-511) (-511) (-511) (-511) (-511) (-511) (-511)
				(-511) (-511) (-511) (-511) (-511) (-511) (-511) (-511) (-511) (-511) (-511) (-511) (-511) (-511) (-511) (-511) (-511) (-511) (-511) (-511) (-511) (-511) (-511) (-511) (-511) (-511) (-511) (-511) (-511) (-511) (-511) (-511)
				(-511) (-511) (-511) (-511) (-511) (-511) (-511) (-511) (-511) (-511) (-511) (-511) (-511) (-511) (-511) (-511) (-511) (-511) (-511) (-511) (-511) (-511) (-511) (-511) (-511) (-511) (-511) (-511) (-511) (-511) (-511) (-511)
				(-511) (-511) (-511) (-511) (-511) (-511) (-511) (-511) (-511) (-511) (-511) (-511) (-511) (-511) (-511) (-511) (-511) (-511) (-511) (-511) (-511) (-511) (-511) (-511) (-511) (-511) (-511) (-511) (-511) (-511) (-511) (-511)
				(-511) (-511) (-511) (-511) (-511) (-511) (-511) (-511) (-511) (-511) (-511) (-511) (-511) (-511) (-511) (-511) (-511) (-511) (-511) (-511) (-511) (-511) (-511) (-511) (-511) (-511) (-511) (-511) (-511) (-511) (-511) (-511)
				(-511) (-511) (-511) (-511) (-511) (-511) (-511) (-511) (-511) (-511) (-511) (-511) (-511) (-511) (-511) (-511) (-511) (-511) (-511) (-511) (-511) (-511) (-511) (-511) (-511) (-511) (-511) (-511) (-511) (-511) (-511) (-511)
				(-511) (-511) (-511) (-511) (-511) (-511) (-511) (-511) (-511) (-511) (-511) (-511) (-511) (-511) (-511) (-511) (-511) (-511) (-511) (-511) (-511) (-511) (-511) (-511) (-511) (-511) (-511) (-511) (-511) (-511) (-511) (-511)
				(-511) (-511) (-511) (-511) (-511) (-511) (-511) (-511) (-511) (-511) (-511) (-511) (-511) (-511) (-511) (-511) (-511) (-511) (-511) (-511) (-511) (-511) (-511) (-511) (-511) (-511) (-511) (-511) (-511) (-511) (-511) (-511)
				(-511) (-511) (-511) (-511) (-511) (-511) (-511) (-511) (-511) (-511) (-511) (-511) (-511) (-511) (-511) (-511) (-511) (-511) (-511) (-511) (-511) (-511) (-511) (-511) (-511) (-511) (-511) (-511) (-511) (-511) (-511) (-511)
				(-511) (-511) (-511) (-511) (-511) (-511) (-511) (-511) (-511) (-511) (-511) (-511) (-511) (-511) (-511) (-511) (-511) (-511) (-511) (-511) (-511) (-511) (-511) (-511) (-511) (-511) (-511) (-511) (-511) (-511) (-511) (-511)
				(-511) (-511) (-511) (-511) (-511) (-511) (-511) (-511) (-511) (-511) (-511) (-511) (-511) (-511) (-511) (-511) (-511) (-511) (-511) (-511) (-511) (-511) (-511) (-511) (-511) (-511) (-511) (-511) (-511) (-511) (-511) (-511)
				(-511) (-511) (-511) (-511) (-511) (-511) (-511) (-511) (-511) (-511) (-511) (-511) (-511) (-511) (-511) (-511) (-511) (-511) (-511) (-511) (-511) (-511) (-511) (-511) (-511) (-511) (-511) (-511) (-511) (-511) (-511) (-511)
				(-511) (-511) (-511) (-511) (-511) (-511) (-511) (-511) (-511) (-511) (-511) (-511) (-511) (-511) (-511) (-511) (-511) (-511) (-511) (-511) (-511) (-511) (-511) (-511) (-511) (-511) (-511) (-511) (-511) (-511) (-511) (-511)
				(-511) (-511) (-511)>;

			PS_Config_Lmt_FW_Rawdata_P = <
				3840 3840 3840 3840 3840 3840 3840 3840 3840 3840 3840 3840 3840 3840 3840 3840 3840 3840 3840 3840 3840 3840 3840 3840 3840 3840 3840 3840 3840 3840 3840 3840
				3840 3840 3840 3840 3840 3840 3840 3840 3840 3840 3840 3840 3840 3840 3840 3840 3840 3840 3840 3840 3840 3840 3840 3840 3840 3840 3840 3840 3840 3840 3840 3840
				3840 3840 3840 3840 3840 3840 3840 3840 3840 3840 3840 3840 3840 3840 3840 3840 3840 3840 3840 3840 3840 3840 3840 3840 3840 3840 3840 3840 3840 3840 3840 3840
				3840 3840 3840 3840 3840 3840 3840 3840 3840 3840 3840 3840 3840 3840 3840 3840 3840 3840 3840 3840 3840 3840 3840 3840 3840 3840 3840 3840 3840 3840 3840 3840
				3840 3840 3840 3840 3840 3840 3840 3840 3840 3840 3840 3840 3840 3840 3840 3840 3840 3840 3840 3840 3840 3840 3840 3840 3840 3840 3840 3840 3840 3840 3840 3840
				3840 3840 3840 3840 3840 3840 3840 3840 3840 3840 3840 3840 3840 3840 3840 3840 3840 3840 3840 3840 3840 3840 3840 3840 3840 3840 3840 3840 3840 3840 3840 3840
				3840 3840 3840 3840 3840 3840 3840 3840 3840 3840 3840 3840 3840 3840 3840 3840 3840 3840 3840 3840 3840 3840 3840 3840 3840 3840 3840 3840 3840 3840 3840 3840
				3840 3840 3840 3840 3840 3840 3840 3840 3840 3840 3840 3840 3840 3840 3840 3840 3840 3840 3840 3840 3840 3840 3840 3840 3840 3840 3840 3840 3840 3840 3840 3840
				3840 3840 3840 3840 3840 3840 3840 3840 3840 3840 3840 3840 3840 3840 3840 3840 3840 3840 3840 3840 3840 3840 3840 3840 3840 3840 3840 3840 3840 3840 3840 3840
				3840 3840 3840 3840 3840 3840 3840 3840 3840 3840 3840 3840 3840 3840 3840 3840 3840 3840 3840 3840 3840 3840 3840 3840 3840 3840 3840 3840 3840 3840 3840 3840
				3840 3840 3840 3840 3840 3840 3840 3840 3840 3840 3840 3840 3840 3840 3840 3840 3840 3840 3840 3840 3840 3840 3840 3840 3840 3840 3840 3840 3840 3840 3840 3840
				3840 3840 3840 3840 3840 3840 3840 3840 3840 3840 3840 3840 3840 3840 3840 3840 3840 3840 3840 3840 3840 3840 3840 3840 3840 3840 3840 3840 3840 3840 3840 3840
				3840 3840 3840 3840 3840 3840 3840 3840 3840 3840 3840 3840 3840 3840 3840 3840 3840 3840 3840 3840 3840 3840 3840 3840 3840 3840 3840 3840 3840 3840 3840 3840
				3840 3840 3840 3840 3840 3840 3840 3840 3840 3840 3840 3840 3840 3840 3840 3840 3840 3840 3840 3840 3840 3840 3840 3840 3840 3840 3840 3840 3840 3840 3840 3840
				3840 3840 3840 3840 3840 3840 3840 3840 3840 3840 3840 3840 3840 3840 3840 3840 3840 3840 3840 3840 3840 3840 3840 3840 3840 3840 3840 3840 3840 3840 3840 3840
				3840 3840 3840 3840 3840 3840 3840 3840 3840 3840 3840 3840 3840 3840 3840 3840 3840 3840 3840 3840 3840 3840 3840 3840 3840 3840 3840 3840 3840 3840 3840 3840
				3840 3840 3840 3840 3840 3840 3840 3840 3840 3840 3840 3840 3840 3840 3840 3840 3840 3840 3840 3840 3840 3840 3840 3840 3840 3840 3840 3840 3840 3840 3840 3840
				3840 3840 3840 3840 3840 3840 3840 3840 3840 3840 3840 3840 3840 3840 3840 3840 3840 3840 3840 3840 3840 3840 3840 3840 3840 3840 3840 3840 3840 3840 3840 3840
				3840 3840 3840 3840 3840 3840 3840 3840 3840 3840 3840 3840 3840 3840 3840 3840 3840 3840 3840 3840 3840 3840 3840 3840 3840 3840 3840 3840 3840 3840 3840 3840
				3840 3840 3840 3840 3840 3840 3840 3840 3840 3840 3840 3840 3840 3840 3840 3840 3840 3840 3840 3840 3840 3840 3840 3840 3840 3840 3840 3840 3840 3840 3840 3840
				3840 3840 3840 3840 3840 3840 3840 3840 3840 3840 3840 3840 3840 3840 3840 3840 3840 3840 3840 3840 3840 3840 3840 3840 3840 3840 3840 3840 3840 3840 3840 3840
				3840 3840 3840 3840 3840 3840 3840 3840 3840 3840 3840 3840 3840 3840 3840 3840 3840 3840 3840 3840 3840 3840 3840 3840 3840 3840 3840 3840 3840 3840 3840 3840
				3840 3840 3840 3840 3840 3840 3840 3840 3840 3840 3840 3840 3840 3840 3840 3840 3840 3840 3840 3840 3840 3840 3840 3840 3840 3840 3840 3840 3840 3840 3840 3840
				3840 3840 3840 3840 3840 3840 3840 3840 3840 3840 3840 3840 3840 3840 3840 3840 3840 3840 3840 3840 3840 3840 3840 3840 3840 3840 3840 3840 3840 3840 3840 3840
				3840 3840 3840 3840 3840 3840 3840 3840 3840 3840 3840 3840 3840 3840 3840 3840 3840 3840 3840 3840 3840 3840 3840 3840 3840 3840 3840 3840 3840 3840 3840 3840
				3840 3840 3840 3840 3840 3840 3840 3840 3840 3840 3840 3840 3840 3840 3840 3840 3840 3840 3840 3840 3840 3840 3840 3840 3840 3840 3840 3840 3840 3840 3840 3840
				3840 3840 3840 3840 3840 3840 3840 3840 3840 3840 3840 3840 3840 3840 3840 3840 3840 3840 3840 3840 3840 3840 3840 3840 3840 3840 3840 3840 3840 3840 3840 3840
				3840 3840 3840 3840 3840 3840 3840 3840 3840 3840 3840 3840 3840 3840 3840 3840 3840 3840 3840 3840 3840 3840 3840 3840 3840 3840 3840 3840 3840 3840 3840 3840
				3840 3840 3840 3840 3840 3840 3840 3840 3840 3840 3840 3840 3840 3840 3840 3840 3840 3840 3840 3840 3840 3840 3840 3840 3840 3840 3840 3840 3840 3840 3840 3840
				3840 3840 3840 3840 3840 3840 3840 3840 3840 3840 3840 3840 3840 3840 3840 3840 3840 3840 3840 3840 3840 3840 3840 3840 3840 3840 3840 3840 3840 3840 3840 3840
				3840 3840 3840 3840 3840 3840 3840 3840 3840 3840 3840 3840 3840 3840 3840 3840 3840 3840 3840 3840 3840 3840 3840 3840 3840 3840 3840 3840 3840 3840 3840 3840
				3840 3840 3840 3840 3840 3840 3840 3840 3840 3840 3840 3840 3840 3840 3840 3840 3840 3840 3840 3840 3840 3840 3840 3840 3840 3840 3840 3840 3840 3840 3840 3840
				3840 3840 3840 3840 3840 3840 3840 3840 3840 3840 3840 3840 3840 3840 3840 3840 3840 3840 3840 3840 3840 3840 3840 3840 3840 3840 3840 3840 3840 3840 3840 3840
				3840 3840 3840 3840 3840 3840 3840 3840 3840 3840 3840 3840 3840 3840 3840 3840 3840 3840 3840 3840 3840 3840 3840 3840 3840 3840 3840 3840 3840 3840 3840 3840
				3840 3840 3840 3840 3840 3840 3840 3840 3840 3840 3840 3840 3840 3840 3840 3840 3840 3840 3840 3840 3840 3840 3840 3840 3840 3840 3840 3840 3840 3840 3840 3840
				3840 3840 3840 3840 3840 3840 3840 3840 3840 3840 3840 3840 3840 3840 3840 3840 3840 3840 3840 3840 3840 3840 3840 3840 3840 3840 3840 3840 3840 3840 3840 3840
				3840 3840 3840 3840 3840 3840 3840 3840 3840 3840 3840 3840 3840 3840 3840 3840 3840 3840 3840 3840 3840 3840 3840 3840 3840 3840 3840 3840 3840 3840 3840 3840
				3840 3840 3840 3840 3840 3840 3840 3840 3840 3840 3840 3840 3840 3840 3840 3840 3840 3840 3840 3840 3840 3840 3840 3840 3840 3840 3840 3840 3840 3840 3840 3840
				3840 3840 3840 3840 3840 3840 3840 3840 3840 3840 3840 3840 3840 3840 3840 3840 3840 3840 3840 3840 3840 3840 3840 3840 3840 3840 3840 3840 3840 3840 3840 3840
				3840 3840 3840 3840 3840 3840 3840 3840 3840 3840 3840 3840 3840 3840 3840 3840 3840 3840 3840 3840 3840 3840 3840 3840 3840 3840 3840 3840 3840 3840 3840 3840
				3840 3840 3840 3840 3840 3840 3840 3840 3840 3840 3840 3840 3840 3840 3840 3840 3840 3840 3840 3840 3840 3840 3840 3840 3840 3840 3840 3840 3840 3840 3840 3840
				3840 3840 3840 3840 3840 3840 3840 3840 3840 3840 3840 3840 3840 3840 3840 3840 3840 3840 3840 3840 3840 3840 3840 3840 3840 3840 3840 3840 3840 3840 3840 3840
				3840 3840 3840 3840 3840 3840 3840 3840 3840 3840 3840 3840 3840 3840 3840 3840 3840 3840 3840 3840 3840 3840 3840 3840 3840 3840 3840 3840 3840 3840 3840 3840
				3840 3840 3840 3840 3840 3840 3840 3840 3840 3840 3840 3840 3840 3840 3840 3840 3840 3840 3840 3840 3840 3840 3840 3840 3840 3840 3840 3840 3840 3840 3840 3840
				3840 3840 3840 3840 3840 3840 3840 3840 3840 3840 3840 3840 3840 3840 3840 3840 3840 3840 3840 3840 3840 3840 3840 3840 3840 3840 3840 3840 3840 3840 3840 3840
				3840 3840 3840 3840 3840 3840 3840 3840 3840 3840 3840 3840 3840 3840 3840 3840 3840 3840 3840 3840 3840 3840 3840 3840 3840 3840 3840 3840 3840 3840 3840 3840
				3840 3840 3840 3840 3840 3840 3840 3840 3840 3840 3840 3840 3840 3840 3840 3840 3840 3840 3840 3840 3840 3840 3840 3840 3840 3840 3840 3840 3840 3840 3840 3840
				3840 3840 3840 3840 3840 3840 3840 3840 3840 3840 3840 3840 3840 3840 3840 3840 3840 3840 3840 3840 3840 3840 3840 3840 3840 3840 3840 3840 3840 3840 3840 3840
				3840 3840 3840 3840 3840 3840 3840 3840 3840 3840 3840 3840 3840 3840 3840 3840 3840 3840 3840 3840 3840 3840 3840 3840 3840 3840 3840 3840 3840 3840 3840 3840
				3840 3840 3840 3840 3840 3840 3840 3840 3840 3840 3840 3840 3840 3840 3840 3840 3840 3840 3840 3840 3840 3840 3840 3840 3840 3840 3840 3840 3840 3840 3840 3840
				3840 3840 3840>;

			PS_Config_Lmt_FW_Rawdata_N = <
				240 240 240 240 240 240 240 240 240 240 240 240 240 240 240 240 240 240 240 240 240 240 240 240 240 240 240 240 240 240 240 240
				240 240 240 240 240 240 240 240 240 240 240 240 240 240 240 240 240 240 240 240 240 240 240 240 240 240 240 240 240 240 240 240
				240 240 240 240 240 240 240 240 240 240 240 240 240 240 240 240 240 240 240 240 240 240 240 240 240 240 240 240 240 240 240 240
				240 240 240 240 240 240 240 240 240 240 240 240 240 240 240 240 240 240 240 240 240 240 240 240 240 240 240 240 240 240 240 240
				240 240 240 240 240 240 240 240 240 240 240 240 240 240 240 240 240 240 240 240 240 240 240 240 240 240 240 240 240 240 240 240
				240 240 240 240 240 240 240 240 240 240 240 240 240 240 240 240 240 240 240 240 240 240 240 240 240 240 240 240 240 240 240 240
				240 240 240 240 240 240 240 240 240 240 240 240 240 240 240 240 240 240 240 240 240 240 240 240 240 240 240 240 240 240 240 240
				240 240 240 240 240 240 240 240 240 240 240 240 240 240 240 240 240 240 240 240 240 240 240 240 240 240 240 240 240 240 240 240
				240 240 240 240 240 240 240 240 240 240 240 240 240 240 240 240 240 240 240 240 240 240 240 240 240 240 240 240 240 240 240 240
				240 240 240 240 240 240 240 240 240 240 240 240 240 240 240 240 240 240 240 240 240 240 240 240 240 240 240 240 240 240 240 240
				240 240 240 240 240 240 240 240 240 240 240 240 240 240 240 240 240 240 240 240 240 240 240 240 240 240 240 240 240 240 240 240
				240 240 240 240 240 240 240 240 240 240 240 240 240 240 240 240 240 240 240 240 240 240 240 240 240 240 240 240 240 240 240 240
				240 240 240 240 240 240 240 240 240 240 240 240 240 240 240 240 240 240 240 240 240 240 240 240 240 240 240 240 240 240 240 240
				240 240 240 240 240 240 240 240 240 240 240 240 240 240 240 240 240 240 240 240 240 240 240 240 240 240 240 240 240 240 240 240
				240 240 240 240 240 240 240 240 240 240 240 240 240 240 240 240 240 240 240 240 240 240 240 240 240 240 240 240 240 240 240 240
				240 240 240 240 240 240 240 240 240 240 240 240 240 240 240 240 240 240 240 240 240 240 240 240 240 240 240 240 240 240 240 240
				240 240 240 240 240 240 240 240 240 240 240 240 240 240 240 240 240 240 240 240 240 240 240 240 240 240 240 240 240 240 240 240
				240 240 240 240 240 240 240 240 240 240 240 240 240 240 240 240 240 240 240 240 240 240 240 240 240 240 240 240 240 240 240 240
				240 240 240 240 240 240 240 240 240 240 240 240 240 240 240 240 240 240 240 240 240 240 240 240 240 240 240 240 240 240 240 240
				240 240 240 240 240 240 240 240 240 240 240 240 240 240 240 240 240 240 240 240 240 240 240 240 240 240 240 240 240 240 240 240
				240 240 240 240 240 240 240 240 240 240 240 240 240 240 240 240 240 240 240 240 240 240 240 240 240 240 240 240 240 240 240 240
				240 240 240 240 240 240 240 240 240 240 240 240 240 240 240 240 240 240 240 240 240 240 240 240 240 240 240 240 240 240 240 240
				240 240 240 240 240 240 240 240 240 240 240 240 240 240 240 240 240 240 240 240 240 240 240 240 240 240 240 240 240 240 240 240
				240 240 240 240 240 240 240 240 240 240 240 240 240 240 240 240 240 240 240 240 240 240 240 240 240 240 240 240 240 240 240 240
				240 240 240 240 240 240 240 240 240 240 240 240 240 240 240 240 240 240 240 240 240 240 240 240 240 240 240 240 240 240 240 240
				240 240 240 240 240 240 240 240 240 240 240 240 240 240 240 240 240 240 240 240 240 240 240 240 240 240 240 240 240 240 240 240
				240 240 240 240 240 240 240 240 240 240 240 240 240 240 240 240 240 240 240 240 240 240 240 240 240 240 240 240 240 240 240 240
				240 240 240 240 240 240 240 240 240 240 240 240 240 240 240 240 240 240 240 240 240 240 240 240 240 240 240 240 240 240 240 240
				240 240 240 240 240 240 240 240 240 240 240 240 240 240 240 240 240 240 240 240 240 240 240 240 240 240 240 240 240 240 240 240
				240 240 240 240 240 240 240 240 240 240 240 240 240 240 240 240 240 240 240 240 240 240 240 240 240 240 240 240 240 240 240 240
				240 240 240 240 240 240 240 240 240 240 240 240 240 240 240 240 240 240 240 240 240 240 240 240 240 240 240 240 240 240 240 240
				240 240 240 240 240 240 240 240 240 240 240 240 240 240 240 240 240 240 240 240 240 240 240 240 240 240 240 240 240 240 240 240
				240 240 240 240 240 240 240 240 240 240 240 240 240 240 240 240 240 240 240 240 240 240 240 240 240 240 240 240 240 240 240 240
				240 240 240 240 240 240 240 240 240 240 240 240 240 240 240 240 240 240 240 240 240 240 240 240 240 240 240 240 240 240 240 240
				240 240 240 240 240 240 240 240 240 240 240 240 240 240 240 240 240 240 240 240 240 240 240 240 240 240 240 240 240 240 240 240
				240 240 240 240 240 240 240 240 240 240 240 240 240 240 240 240 240 240 240 240 240 240 240 240 240 240 240 240 240 240 240 240
				240 240 240 240 240 240 240 240 240 240 240 240 240 240 240 240 240 240 240 240 240 240 240 240 240 240 240 240 240 240 240 240
				240 240 240 240 240 240 240 240 240 240 240 240 240 240 240 240 240 240 240 240 240 240 240 240 240 240 240 240 240 240 240 240
				240 240 240 240 240 240 240 240 240 240 240 240 240 240 240 240 240 240 240 240 240 240 240 240 240 240 240 240 240 240 240 240
				240 240 240 240 240 240 240 240 240 240 240 240 240 240 240 240 240 240 240 240 240 240 240 240 240 240 240 240 240 240 240 240
				240 240 240 240 240 240 240 240 240 240 240 240 240 240 240 240 240 240 240 240 240 240 240 240 240 240 240 240 240 240 240 240
				240 240 240 240 240 240 240 240 240 240 240 240 240 240 240 240 240 240 240 240 240 240 240 240 240 240 240 240 240 240 240 240
				240 240 240 240 240 240 240 240 240 240 240 240 240 240 240 240 240 240 240 240 240 240 240 240 240 240 240 240 240 240 240 240
				240 240 240 240 240 240 240 240 240 240 240 240 240 240 240 240 240 240 240 240 240 240 240 240 240 240 240 240 240 240 240 240
				240 240 240 240 240 240 240 240 240 240 240 240 240 240 240 240 240 240 240 240 240 240 240 240 240 240 240 240 240 240 240 240
				240 240 240 240 240 240 240 240 240 240 240 240 240 240 240 240 240 240 240 240 240 240 240 240 240 240 240 240 240 240 240 240
				240 240 240 240 240 240 240 240 240 240 240 240 240 240 240 240 240 240 240 240 240 240 240 240 240 240 240 240 240 240 240 240
				240 240 240 240 240 240 240 240 240 240 240 240 240 240 240 240 240 240 240 240 240 240 240 240 240 240 240 240 240 240 240 240
				240 240 240 240 240 240 240 240 240 240 240 240 240 240 240 240 240 240 240 240 240 240 240 240 240 240 240 240 240 240 240 240
				240 240 240 240 240 240 240 240 240 240 240 240 240 240 240 240 240 240 240 240 240 240 240 240 240 240 240 240 240 240 240 240
				240 240 240>;

			PS_Config_Lmt_FW_CC_P = <
				314 314 314 314 314 314 314 314 314 314 314 314 314 314 314 314 314 314 314 314 314 314 314 314 314 314 314 314 314 314 314 314
				314 314 314 314 314 314 314 314 314 314 314 314 314 314 314 314 314 314 314 314 314 314 314 314 314 314 314 314 314 314 314 314
				314 314 314 314 314 314 314 314 314 314 314 314 314 314 314 314 314 314 314 314 314 314 314 314 314 314 314 314 314 314 314 314
				314 314 314 314 314 314 314 314 314 314 314 314 314 314 314 314 314 314 314 314 314 314 314 314 314 314 314 314 314 314 314 314
				314 314 314 314 314 314 314 314 314 314 314 314 314 314 314 314 314 314 314 314 314 314 314 314 314 314 314 314 314 314 314 314
				314 314 314 314 314 314 314 314 314 314 314 314 314 314 314 314 314 314 314 314 314 314 314 314 314 314 314 314 314 314 314 314
				314 314 314 314 314 314 314 314 314 314 314 314 314 314 314 314 314 314 314 314 314 314 314 314 314 314 314 314 314 314 314 314
				314 314 314 314 314 314 314 314 314 314 314 314 314 314 314 314 314 314 314 314 314 314 314 314 314 314 314 314 314 314 314 314
				314 314 314 314 314 314 314 314 314 314 314 314 314 314 314 314 314 314 314 314 314 314 314 314 314 314 314 314 314 314 314 314
				314 314 314 314 314 314 314 314 314 314 314 314 314 314 314 314 314 314 314 314 314 314 314 314 314 314 314 314 314 314 314 314
				314 314 314 314 314 314 314 314 314 314 314 314 314 314 314 314 314 314 314 314 314 314 314 314 314 314 314 314 314 314 314 314
				314 314 314 314 314 314 314 314 314 314 314 314 314 314 314 314 314 314 314 314 314 314 314 314 314 314 314 314 314 314 314 314
				314 314 314 314 314 314 314 314 314 314 314 314 314 314 314 314 314 314 314 314 314 314 314 314 314 314 314 314 314 314 314 314
				314 314 314 314 314 314 314 314 314 314 314 314 314 314 314 314 314 314 314 314 314 314 314 314 314 314 314 314 314 314 314 314
				314 314 314 314 314 314 314 314 314 314 314 314 314 314 314 314 314 314 314 314 314 314 314 314 314 314 314 314 314 314 314 314
				314 314 314 314 314 314 314 314 314 314 314 314 314 314 314 314 314 314 314 314 314 314 314 314 314 314 314 314 314 314 314 314
				314 314 314 314 314 314 314 314 314 314 314 314 314 314 314 314 314 314 314 314 314 314 314 314 314 314 314 314 314 314 314 314
				314 314 314 314 314 314 314 314 314 314 314 314 314 314 314 314 314 314 314 314 314 314 314 314 314 314 314 314 314 314 314 314
				314 314 314 314 314 314 314 314 314 314 314 314 314 314 314 314 314 314 314 314 314 314 314 314 314 314 314 314 314 314 314 314
				314 314 314 314 314 314 314 314 314 314 314 314 314 314 314 314 314 314 314 314 314 314 314 314 314 314 314 314 314 314 314 314
				314 314 314 314 314 314 314 314 314 314 314 314 314 314 314 314 314 314 314 314 314 314 314 314 314 314 314 314 314 314 314 314
				314 314 314 314 314 314 314 314 314 314 314 314 314 314 314 314 314 314 314 314 314 314 314 314 314 314 314 314 314 314 314 314
				314 314 314 314 314 314 314 314 314 314 314 314 314 314 314 314 314 314 314 314 314 314 314 314 314 314 314 314 314 314 314 314
				314 314 314 314 314 314 314 314 314 314 314 314 314 314 314 314 314 314 314 314 314 314 314 314 314 314 314 314 314 314 314 314
				314 314 314 314 314 314 314 314 314 314 314 314 314 314 314 314 314 314 314 314 314 314 314 314 314 314 314 314 314 314 314 314
				314 314 314 314 314 314 314 314 314 314 314 314 314 314 314 314 314 314 314 314 314 314 314 314 314 314 314 314 314 314 314 314
				314 314 314 314 314 314 314 314 314 314 314 314 314 314 314 314 314 314 314 314 314 314 314 314 314 314 314 314 314 314 314 314
				314 314 314 314 314 314 314 314 314 314 314 314 314 314 314 314 314 314 314 314 314 314 314 314 314 314 314 314 314 314 314 314
				314 314 314 314 314 314 314 314 314 314 314 314 314 314 314 314 314 314 314 314 314 314 314 314 314 314 314 314 314 314 314 314
				314 314 314 314 314 314 314 314 314 314 314 314 314 314 314 314 314 314 314 314 314 314 314 314 314 314 314 314 314 314 314 314
				314 314 314 314 314 314 314 314 314 314 314 314 314 314 314 314 314 314 314 314 314 314 314 314 314 314 314 314 314 314 314 314
				314 314 314 314 314 314 314 314 314 314 314 314 314 314 314 314 314 314 314 314 314 314 314 314 314 314 314 314 314 314 314 314
				314 314 314 314 314 314 314 314 314 314 314 314 314 314 314 314 314 314 314 314 314 314 314 314 314 314 314 314 314 314 314 314
				314 314 314 314 314 314 314 314 314 314 314 314 314 314 314 314 314 314 314 314 314 314 314 314 314 314 314 314 314 314 314 314
				314 314 314 314 314 314 314 314 314 314 314 314 314 314 314 314 314 314 314 314 314 314 314 314 314 314 314 314 314 314 314 314
				314 314 314 314 314 314 314 314 314 314 314 314 314 314 314 314 314 314 314 314 314 314 314 314 314 314 314 314 314 314 314 314
				314 314 314 314 314 314 314 314 314 314 314 314 314 314 314 314 314 314 314 314 314 314 314 314 314 314 314 314 314 314 314 314
				314 314 314 314 314 314 314 314 314 314 314 314 314 314 314 314 314 314 314 314 314 314 314 314 314 314 314 314 314 314 314 314
				314 314 314 314 314 314 314 314 314 314 314 314 314 314 314 314 314 314 314 314 314 314 314 314 314 314 314 314 314 314 314 314
				314 314 314 314 314 314 314 314 314 314 314 314 314 314 314 314 314 314 314 314 314 314 314 314 314 314 314 314 314 314 314 314
				314 314 314 314 314 314 314 314 314 314 314 314 314 314 314 314 314 314 314 314 314 314 314 314 314 314 314 314 314 314 314 314
				314 314 314 314 314 314 314 314 314 314 314 314 314 314 314 314 314 314 314 314 314 314 314 314 314 314 314 314 314 314 314 314
				314 314 314 314 314 314 314 314 314 314 314 314 314 314 314 314 314 314 314 314 314 314 314 314 314 314 314 314 314 314 314 314
				314 314 314 314 314 314 314 314 314 314 314 314 314 314 314 314 314 314 314 314 314 314 314 314 314 314 314 314 314 314 314 314
				314 314 314 314 314 314 314 314 314 314 314 314 314 314 314 314 314 314 314 314 314 314 314 314 314 314 314 314 314 314 314 314
				314 314 314 314 314 314 314 314 314 314 314 314 314 314 314 314 314 314 314 314 314 314 314 314 314 314 314 314 314 314 314 314
				314 314 314 314 314 314 314 314 314 314 314 314 314 314 314 314 314 314 314 314 314 314 314 314 314 314 314 314 314 314 314 314
				314 314 314 314 314 314 314 314 314 314 314 314 314 314 314 314 314 314 314 314 314 314 314 314 314 314 314 314 314 314 314 314
				314 314 314 314 314 314 314 314 314 314 314 314 314 314 314 314 314 314 314 314 314 314 314 314 314 314 314 314 314 314 314 314
				314 314 314 314 314 314 314 314 314 314 314 314 314 314 314 314 314 314 314 314 314 314 314 314 314 314 314 314 314 314 314 314
				314 314 314>;

			PS_Config_Lmt_FW_CC_N = <
				0 0 0 0 0 0 0 0 0 0 0 0 0 0 0 0 0 0 0 0 0 0 0 0 0 0 0 0 0 0 0 0
				0 0 0 0 0 0 0 0 0 0 0 0 0 0 0 0 0 0 0 0 0 0 0 0 0 0 0 0 0 0 0 0
				0 0 0 0 0 0 0 0 0 0 0 0 0 0 0 0 0 0 0 0 0 0 0 0 0 0 0 0 0 0 0 0
				0 0 0 0 0 0 0 0 0 0 0 0 0 0 0 0 0 0 0 0 0 0 0 0 0 0 0 0 0 0 0 0
				0 0 0 0 0 0 0 0 0 0 0 0 0 0 0 0 0 0 0 0 0 0 0 0 0 0 0 0 0 0 0 0
				0 0 0 0 0 0 0 0 0 0 0 0 0 0 0 0 0 0 0 0 0 0 0 0 0 0 0 0 0 0 0 0
				0 0 0 0 0 0 0 0 0 0 0 0 0 0 0 0 0 0 0 0 0 0 0 0 0 0 0 0 0 0 0 0
				0 0 0 0 0 0 0 0 0 0 0 0 0 0 0 0 0 0 0 0 0 0 0 0 0 0 0 0 0 0 0 0
				0 0 0 0 0 0 0 0 0 0 0 0 0 0 0 0 0 0 0 0 0 0 0 0 0 0 0 0 0 0 0 0
				0 0 0 0 0 0 0 0 0 0 0 0 0 0 0 0 0 0 0 0 0 0 0 0 0 0 0 0 0 0 0 0
				0 0 0 0 0 0 0 0 0 0 0 0 0 0 0 0 0 0 0 0 0 0 0 0 0 0 0 0 0 0 0 0
				0 0 0 0 0 0 0 0 0 0 0 0 0 0 0 0 0 0 0 0 0 0 0 0 0 0 0 0 0 0 0 0
				0 0 0 0 0 0 0 0 0 0 0 0 0 0 0 0 0 0 0 0 0 0 0 0 0 0 0 0 0 0 0 0
				0 0 0 0 0 0 0 0 0 0 0 0 0 0 0 0 0 0 0 0 0 0 0 0 0 0 0 0 0 0 0 0
				0 0 0 0 0 0 0 0 0 0 0 0 0 0 0 0 0 0 0 0 0 0 0 0 0 0 0 0 0 0 0 0
				0 0 0 0 0 0 0 0 0 0 0 0 0 0 0 0 0 0 0 0 0 0 0 0 0 0 0 0 0 0 0 0
				0 0 0 0 0 0 0 0 0 0 0 0 0 0 0 0 0 0 0 0 0 0 0 0 0 0 0 0 0 0 0 0
				0 0 0 0 0 0 0 0 0 0 0 0 0 0 0 0 0 0 0 0 0 0 0 0 0 0 0 0 0 0 0 0
				0 0 0 0 0 0 0 0 0 0 0 0 0 0 0 0 0 0 0 0 0 0 0 0 0 0 0 0 0 0 0 0
				0 0 0 0 0 0 0 0 0 0 0 0 0 0 0 0 0 0 0 0 0 0 0 0 0 0 0 0 0 0 0 0
				0 0 0 0 0 0 0 0 0 0 0 0 0 0 0 0 0 0 0 0 0 0 0 0 0 0 0 0 0 0 0 0
				0 0 0 0 0 0 0 0 0 0 0 0 0 0 0 0 0 0 0 0 0 0 0 0 0 0 0 0 0 0 0 0
				0 0 0 0 0 0 0 0 0 0 0 0 0 0 0 0 0 0 0 0 0 0 0 0 0 0 0 0 0 0 0 0
				0 0 0 0 0 0 0 0 0 0 0 0 0 0 0 0 0 0 0 0 0 0 0 0 0 0 0 0 0 0 0 0
				0 0 0 0 0 0 0 0 0 0 0 0 0 0 0 0 0 0 0 0 0 0 0 0 0 0 0 0 0 0 0 0
				0 0 0 0 0 0 0 0 0 0 0 0 0 0 0 0 0 0 0 0 0 0 0 0 0 0 0 0 0 0 0 0
				0 0 0 0 0 0 0 0 0 0 0 0 0 0 0 0 0 0 0 0 0 0 0 0 0 0 0 0 0 0 0 0
				0 0 0 0 0 0 0 0 0 0 0 0 0 0 0 0 0 0 0 0 0 0 0 0 0 0 0 0 0 0 0 0
				0 0 0 0 0 0 0 0 0 0 0 0 0 0 0 0 0 0 0 0 0 0 0 0 0 0 0 0 0 0 0 0
				0 0 0 0 0 0 0 0 0 0 0 0 0 0 0 0 0 0 0 0 0 0 0 0 0 0 0 0 0 0 0 0
				0 0 0 0 0 0 0 0 0 0 0 0 0 0 0 0 0 0 0 0 0 0 0 0 0 0 0 0 0 0 0 0
				0 0 0 0 0 0 0 0 0 0 0 0 0 0 0 0 0 0 0 0 0 0 0 0 0 0 0 0 0 0 0 0
				0 0 0 0 0 0 0 0 0 0 0 0 0 0 0 0 0 0 0 0 0 0 0 0 0 0 0 0 0 0 0 0
				0 0 0 0 0 0 0 0 0 0 0 0 0 0 0 0 0 0 0 0 0 0 0 0 0 0 0 0 0 0 0 0
				0 0 0 0 0 0 0 0 0 0 0 0 0 0 0 0 0 0 0 0 0 0 0 0 0 0 0 0 0 0 0 0
				0 0 0 0 0 0 0 0 0 0 0 0 0 0 0 0 0 0 0 0 0 0 0 0 0 0 0 0 0 0 0 0
				0 0 0 0 0 0 0 0 0 0 0 0 0 0 0 0 0 0 0 0 0 0 0 0 0 0 0 0 0 0 0 0
				0 0 0 0 0 0 0 0 0 0 0 0 0 0 0 0 0 0 0 0 0 0 0 0 0 0 0 0 0 0 0 0
				0 0 0 0 0 0 0 0 0 0 0 0 0 0 0 0 0 0 0 0 0 0 0 0 0 0 0 0 0 0 0 0
				0 0 0 0 0 0 0 0 0 0 0 0 0 0 0 0 0 0 0 0 0 0 0 0 0 0 0 0 0 0 0 0
				0 0 0 0 0 0 0 0 0 0 0 0 0 0 0 0 0 0 0 0 0 0 0 0 0 0 0 0 0 0 0 0
				0 0 0 0 0 0 0 0 0 0 0 0 0 0 0 0 0 0 0 0 0 0 0 0 0 0 0 0 0 0 0 0
				0 0 0 0 0 0 0 0 0 0 0 0 0 0 0 0 0 0 0 0 0 0 0 0 0 0 0 0 0 0 0 0
				0 0 0 0 0 0 0 0 0 0 0 0 0 0 0 0 0 0 0 0 0 0 0 0 0 0 0 0 0 0 0 0
				0 0 0 0 0 0 0 0 0 0 0 0 0 0 0 0 0 0 0 0 0 0 0 0 0 0 0 0 0 0 0 0
				0 0 0 0 0 0 0 0 0 0 0 0 0 0 0 0 0 0 0 0 0 0 0 0 0 0 0 0 0 0 0 0
				0 0 0 0 0 0 0 0 0 0 0 0 0 0 0 0 0 0 0 0 0 0 0 0 0 0 0 0 0 0 0 0
				0 0 0 0 0 0 0 0 0 0 0 0 0 0 0 0 0 0 0 0 0 0 0 0 0 0 0 0 0 0 0 0
				0 0 0 0 0 0 0 0 0 0 0 0 0 0 0 0 0 0 0 0 0 0 0 0 0 0 0 0 0 0 0 0
				0 0 0 0 0 0 0 0 0 0 0 0 0 0 0 0 0 0 0 0 0 0 0 0 0 0 0 0 0 0 0 0
				0 0 0>;

			PS_Config_Lmt_FW_Diff_P = <
				75 75 75 75 75 75 75 75 75 75 75 75 75 75 75 75 75 75 75 75 75 75 75 75 75 75 75 75 75 75 75 75
				75 75 75 75 75 75 75 75 75 75 75 75 75 75 75 75 75 75 75 75 75 75 75 75 75 75 75 75 75 75 75 75
				75 75 75 75 75 75 75 75 75 75 75 75 75 75 75 75 75 75 75 75 75 75 75 75 75 75 75 75 75 75 75 75
				75 75 75 75 75 75 75 75 75 75 75 75 75 75 75 75 75 75 75 75 75 75 75 75 75 75 75 75 75 75 75 75
				75 75 75 75 75 75 75 75 75 75 75 75 75 75 75 75 75 75 75 75 75 75 75 75 75 75 75 75 75 75 75 75
				75 75 75 75 75 75 75 75 75 75 75 75 75 75 75 75 75 75 75 75 75 75 75 75 75 75 75 75 75 75 75 75
				75 75 75 75 75 75 75 75 75 75 75 75 75 75 75 75 75 75 75 75 75 75 75 75 75 75 75 75 75 75 75 75
				75 75 75 75 75 75 75 75 75 75 75 75 75 75 75 75 75 75 75 75 75 75 75 75 75 75 75 75 75 75 75 75
				75 75 75 75 75 75 75 75 75 75 75 75 75 75 75 75 75 75 75 75 75 75 75 75 75 75 75 75 75 75 75 75
				75 75 75 75 75 75 75 75 75 75 75 75 75 75 75 75 75 75 75 75 75 75 75 75 75 75 75 75 75 75 75 75
				75 75 75 75 75 75 75 75 75 75 75 75 75 75 75 75 75 75 75 75 75 75 75 75 75 75 75 75 75 75 75 75
				75 75 75 75 75 75 75 75 75 75 75 75 75 75 75 75 75 75 75 75 75 75 75 75 75 75 75 75 75 75 75 75
				75 75 75 75 75 75 75 75 75 75 75 75 75 75 75 75 75 75 75 75 75 75 75 75 75 75 75 75 75 75 75 75
				75 75 75 75 75 75 75 75 75 75 75 75 75 75 75 75 75 75 75 75 75 75 75 75 75 75 75 75 75 75 75 75
				75 75 75 75 75 75 75 75 75 75 75 75 75 75 75 75 75 75 75 75 75 75 75 75 75 75 75 75 75 75 75 75
				75 75 75 75 75 75 75 75 75 75 75 75 75 75 75 75 75 75 75 75 75 75 75 75 75 75 75 75 75 75 75 75
				75 75 75 75 75 75 75 75 75 75 75 75 75 75 75 75 75 75 75 75 75 75 75 75 75 75 75 75 75 75 75 75
				75 75 75 75 75 75 75 75 75 75 75 75 75 75 75 75 75 75 75 75 75 75 75 75 75 75 75 75 75 75 75 75
				75 75 75 75 75 75 75 75 75 75 75 75 75 75 75 75 75 75 75 75 75 75 75 75 75 75 75 75 75 75 75 75
				75 75 75 75 75 75 75 75 75 75 75 75 75 75 75 75 75 75 75 75 75 75 75 75 75 75 75 75 75 75 75 75
				75 75 75 75 75 75 75 75 75 75 75 75 75 75 75 75 75 75 75 75 75 75 75 75 75 75 75 75 75 75 75 75
				75 75 75 75 75 75 75 75 75 75 75 75 75 75 75 75 75 75 75 75 75 75 75 75 75 75 75 75 75 75 75 75
				75 75 75 75 75 75 75 75 75 75 75 75 75 75 75 75 75 75 75 75 75 75 75 75 75 75 75 75 75 75 75 75
				75 75 75 75 75 75 75 75 75 75 75 75 75 75 75 75 75 75 75 75 75 75 75 75 75 75 75 75 75 75 75 75
				75 75 75 75 75 75 75 75 75 75 75 75 75 75 75 75 75 75 75 75 75 75 75 75 75 75 75 75 75 75 75 75
				75 75 75 75 75 75 75 75 75 75 75 75 75 75 75 75 75 75 75 75 75 75 75 75 75 75 75 75 75 75 75 75
				75 75 75 75 75 75 75 75 75 75 75 75 75 75 75 75 75 75 75 75 75 75 75 75 75 75 75 75 75 75 75 75
				75 75 75 75 75 75 75 75 75 75 75 75 75 75 75 75 75 75 75 75 75 75 75 75 75 75 75 75 75 75 75 75
				75 75 75 75 75 75 75 75 75 75 75 75 75 75 75 75 75 75 75 75 75 75 75 75 75 75 75 75 75 75 75 75
				75 75 75 75 75 75 75 75 75 75 75 75 75 75 75 75 75 75 75 75 75 75 75 75 75 75 75 75 75 75 75 75
				75 75 75 75 75 75 75 75 75 75 75 75 75 75 75 75 75 75 75 75 75 75 75 75 75 75 75 75 75 75 75 75
				75 75 75 75 75 75 75 75 75 75 75 75 75 75 75 75 75 75 75 75 75 75 75 75 75 75 75 75 75 75 75 75
				75 75 75 75 75 75 75 75 75 75 75 75 75 75 75 75 75 75 75 75 75 75 75 75 75 75 75 75 75 75 75 75
				75 75 75 75 75 75 75 75 75 75 75 75 75 75 75 75 75 75 75 75 75 75 75 75 75 75 75 75 75 75 75 75
				75 75 75 75 75 75 75 75 75 75 75 75 75 75 75 75 75 75 75 75 75 75 75 75 75 75 75 75 75 75 75 75
				75 75 75 75 75 75 75 75 75 75 75 75 75 75 75 75 75 75 75 75 75 75 75 75 75 75 75 75 75 75 75 75
				75 75 75 75 75 75 75 75 75 75 75 75 75 75 75 75 75 75 75 75 75 75 75 75 75 75 75 75 75 75 75 75
				75 75 75 75 75 75 75 75 75 75 75 75 75 75 75 75 75 75 75 75 75 75 75 75 75 75 75 75 75 75 75 75
				75 75 75 75 75 75 75 75 75 75 75 75 75 75 75 75 75 75 75 75 75 75 75 75 75 75 75 75 75 75 75 75
				75 75 75 75 75 75 75 75 75 75 75 75 75 75 75 75 75 75 75 75 75 75 75 75 75 75 75 75 75 75 75 75
				75 75 75 75 75 75 75 75 75 75 75 75 75 75 75 75 75 75 75 75 75 75 75 75 75 75 75 75 75 75 75 75
				75 75 75 75 75 75 75 75 75 75 75 75 75 75 75 75 75 75 75 75 75 75 75 75 75 75 75 75 75 75 75 75
				75 75 75 75 75 75 75 75 75 75 75 75 75 75 75 75 75 75 75 75 75 75 75 75 75 75 75 75 75 75 75 75
				75 75 75 75 75 75 75 75 75 75 75 75 75 75 75 75 75 75 75 75 75 75 75 75 75 75 75 75 75 75 75 75
				75 75 75 75 75 75 75 75 75 75 75 75 75 75 75 75 75 75 75 75 75 75 75 75 75 75 75 75 75 75 75 75
				75 75 75 75 75 75 75 75 75 75 75 75 75 75 75 75 75 75 75 75 75 75 75 75 75 75 75 75 75 75 75 75
				75 75 75 75 75 75 75 75 75 75 75 75 75 75 75 75 75 75 75 75 75 75 75 75 75 75 75 75 75 75 75 75
				75 75 75 75 75 75 75 75 75 75 75 75 75 75 75 75 75 75 75 75 75 75 75 75 75 75 75 75 75 75 75 75
				75 75 75 75 75 75 75 75 75 75 75 75 75 75 75 75 75 75 75 75 75 75 75 75 75 75 75 75 75 75 75 75
				75 75 75 75 75 75 75 75 75 75 75 75 75 75 75 75 75 75 75 75 75 75 75 75 75 75 75 75 75 75 75 75
				75 75 75>;

			PS_Config_Lmt_FW_Diff_N = <
				(-75) (-75) (-75) (-75) (-75) (-75) (-75) (-75) (-75) (-75) (-75) (-75) (-75) (-75) (-75) (-75) (-75) (-75) (-75) (-75) (-75) (-75) (-75) (-75) (-75) (-75) (-75) (-75) (-75) (-75) (-75) (-75)
				(-75) (-75) (-75) (-75) (-75) (-75) (-75) (-75) (-75) (-75) (-75) (-75) (-75) (-75) (-75) (-75) (-75) (-75) (-75) (-75) (-75) (-75) (-75) (-75) (-75) (-75) (-75) (-75) (-75) (-75) (-75) (-75)
				(-75) (-75) (-75) (-75) (-75) (-75) (-75) (-75) (-75) (-75) (-75) (-75) (-75) (-75) (-75) (-75) (-75) (-75) (-75) (-75) (-75) (-75) (-75) (-75) (-75) (-75) (-75) (-75) (-75) (-75) (-75) (-75)
				(-75) (-75) (-75) (-75) (-75) (-75) (-75) (-75) (-75) (-75) (-75) (-75) (-75) (-75) (-75) (-75) (-75) (-75) (-75) (-75) (-75) (-75) (-75) (-75) (-75) (-75) (-75) (-75) (-75) (-75) (-75) (-75)
				(-75) (-75) (-75) (-75) (-75) (-75) (-75) (-75) (-75) (-75) (-75) (-75) (-75) (-75) (-75) (-75) (-75) (-75) (-75) (-75) (-75) (-75) (-75) (-75) (-75) (-75) (-75) (-75) (-75) (-75) (-75) (-75)
				(-75) (-75) (-75) (-75) (-75) (-75) (-75) (-75) (-75) (-75) (-75) (-75) (-75) (-75) (-75) (-75) (-75) (-75) (-75) (-75) (-75) (-75) (-75) (-75) (-75) (-75) (-75) (-75) (-75) (-75) (-75) (-75)
				(-75) (-75) (-75) (-75) (-75) (-75) (-75) (-75) (-75) (-75) (-75) (-75) (-75) (-75) (-75) (-75) (-75) (-75) (-75) (-75) (-75) (-75) (-75) (-75) (-75) (-75) (-75) (-75) (-75) (-75) (-75) (-75)
				(-75) (-75) (-75) (-75) (-75) (-75) (-75) (-75) (-75) (-75) (-75) (-75) (-75) (-75) (-75) (-75) (-75) (-75) (-75) (-75) (-75) (-75) (-75) (-75) (-75) (-75) (-75) (-75) (-75) (-75) (-75) (-75)
				(-75) (-75) (-75) (-75) (-75) (-75) (-75) (-75) (-75) (-75) (-75) (-75) (-75) (-75) (-75) (-75) (-75) (-75) (-75) (-75) (-75) (-75) (-75) (-75) (-75) (-75) (-75) (-75) (-75) (-75) (-75) (-75)
				(-75) (-75) (-75) (-75) (-75) (-75) (-75) (-75) (-75) (-75) (-75) (-75) (-75) (-75) (-75) (-75) (-75) (-75) (-75) (-75) (-75) (-75) (-75) (-75) (-75) (-75) (-75) (-75) (-75) (-75) (-75) (-75)
				(-75) (-75) (-75) (-75) (-75) (-75) (-75) (-75) (-75) (-75) (-75) (-75) (-75) (-75) (-75) (-75) (-75) (-75) (-75) (-75) (-75) (-75) (-75) (-75) (-75) (-75) (-75) (-75) (-75) (-75) (-75) (-75)
				(-75) (-75) (-75) (-75) (-75) (-75) (-75) (-75) (-75) (-75) (-75) (-75) (-75) (-75) (-75) (-75) (-75) (-75) (-75) (-75) (-75) (-75) (-75) (-75) (-75) (-75) (-75) (-75) (-75) (-75) (-75) (-75)
				(-75) (-75) (-75) (-75) (-75) (-75) (-75) (-75) (-75) (-75) (-75) (-75) (-75) (-75) (-75) (-75) (-75) (-75) (-75) (-75) (-75) (-75) (-75) (-75) (-75) (-75) (-75) (-75) (-75) (-75) (-75) (-75)
				(-75) (-75) (-75) (-75) (-75) (-75) (-75) (-75) (-75) (-75) (-75) (-75) (-75) (-75) (-75) (-75) (-75) (-75) (-75) (-75) (-75) (-75) (-75) (-75) (-75) (-75) (-75) (-75) (-75) (-75) (-75) (-75)
				(-75) (-75) (-75) (-75) (-75) (-75) (-75) (-75) (-75) (-75) (-75) (-75) (-75) (-75) (-75) (-75) (-75) (-75) (-75) (-75) (-75) (-75) (-75) (-75) (-75) (-75) (-75) (-75) (-75) (-75) (-75) (-75)
				(-75) (-75) (-75) (-75) (-75) (-75) (-75) (-75) (-75) (-75) (-75) (-75) (-75) (-75) (-75) (-75) (-75) (-75) (-75) (-75) (-75) (-75) (-75) (-75) (-75) (-75) (-75) (-75) (-75) (-75) (-75) (-75)
				(-75) (-75) (-75) (-75) (-75) (-75) (-75) (-75) (-75) (-75) (-75) (-75) (-75) (-75) (-75) (-75) (-75) (-75) (-75) (-75) (-75) (-75) (-75) (-75) (-75) (-75) (-75) (-75) (-75) (-75) (-75) (-75)
				(-75) (-75) (-75) (-75) (-75) (-75) (-75) (-75) (-75) (-75) (-75) (-75) (-75) (-75) (-75) (-75) (-75) (-75) (-75) (-75) (-75) (-75) (-75) (-75) (-75) (-75) (-75) (-75) (-75) (-75) (-75) (-75)
				(-75) (-75) (-75) (-75) (-75) (-75) (-75) (-75) (-75) (-75) (-75) (-75) (-75) (-75) (-75) (-75) (-75) (-75) (-75) (-75) (-75) (-75) (-75) (-75) (-75) (-75) (-75) (-75) (-75) (-75) (-75) (-75)
				(-75) (-75) (-75) (-75) (-75) (-75) (-75) (-75) (-75) (-75) (-75) (-75) (-75) (-75) (-75) (-75) (-75) (-75) (-75) (-75) (-75) (-75) (-75) (-75) (-75) (-75) (-75) (-75) (-75) (-75) (-75) (-75)
				(-75) (-75) (-75) (-75) (-75) (-75) (-75) (-75) (-75) (-75) (-75) (-75) (-75) (-75) (-75) (-75) (-75) (-75) (-75) (-75) (-75) (-75) (-75) (-75) (-75) (-75) (-75) (-75) (-75) (-75) (-75) (-75)
				(-75) (-75) (-75) (-75) (-75) (-75) (-75) (-75) (-75) (-75) (-75) (-75) (-75) (-75) (-75) (-75) (-75) (-75) (-75) (-75) (-75) (-75) (-75) (-75) (-75) (-75) (-75) (-75) (-75) (-75) (-75) (-75)
				(-75) (-75) (-75) (-75) (-75) (-75) (-75) (-75) (-75) (-75) (-75) (-75) (-75) (-75) (-75) (-75) (-75) (-75) (-75) (-75) (-75) (-75) (-75) (-75) (-75) (-75) (-75) (-75) (-75) (-75) (-75) (-75)
				(-75) (-75) (-75) (-75) (-75) (-75) (-75) (-75) (-75) (-75) (-75) (-75) (-75) (-75) (-75) (-75) (-75) (-75) (-75) (-75) (-75) (-75) (-75) (-75) (-75) (-75) (-75) (-75) (-75) (-75) (-75) (-75)
				(-75) (-75) (-75) (-75) (-75) (-75) (-75) (-75) (-75) (-75) (-75) (-75) (-75) (-75) (-75) (-75) (-75) (-75) (-75) (-75) (-75) (-75) (-75) (-75) (-75) (-75) (-75) (-75) (-75) (-75) (-75) (-75)
				(-75) (-75) (-75) (-75) (-75) (-75) (-75) (-75) (-75) (-75) (-75) (-75) (-75) (-75) (-75) (-75) (-75) (-75) (-75) (-75) (-75) (-75) (-75) (-75) (-75) (-75) (-75) (-75) (-75) (-75) (-75) (-75)
				(-75) (-75) (-75) (-75) (-75) (-75) (-75) (-75) (-75) (-75) (-75) (-75) (-75) (-75) (-75) (-75) (-75) (-75) (-75) (-75) (-75) (-75) (-75) (-75) (-75) (-75) (-75) (-75) (-75) (-75) (-75) (-75)
				(-75) (-75) (-75) (-75) (-75) (-75) (-75) (-75) (-75) (-75) (-75) (-75) (-75) (-75) (-75) (-75) (-75) (-75) (-75) (-75) (-75) (-75) (-75) (-75) (-75) (-75) (-75) (-75) (-75) (-75) (-75) (-75)
				(-75) (-75) (-75) (-75) (-75) (-75) (-75) (-75) (-75) (-75) (-75) (-75) (-75) (-75) (-75) (-75) (-75) (-75) (-75) (-75) (-75) (-75) (-75) (-75) (-75) (-75) (-75) (-75) (-75) (-75) (-75) (-75)
				(-75) (-75) (-75) (-75) (-75) (-75) (-75) (-75) (-75) (-75) (-75) (-75) (-75) (-75) (-75) (-75) (-75) (-75) (-75) (-75) (-75) (-75) (-75) (-75) (-75) (-75) (-75) (-75) (-75) (-75) (-75) (-75)
				(-75) (-75) (-75) (-75) (-75) (-75) (-75) (-75) (-75) (-75) (-75) (-75) (-75) (-75) (-75) (-75) (-75) (-75) (-75) (-75) (-75) (-75) (-75) (-75) (-75) (-75) (-75) (-75) (-75) (-75) (-75) (-75)
				(-75) (-75) (-75) (-75) (-75) (-75) (-75) (-75) (-75) (-75) (-75) (-75) (-75) (-75) (-75) (-75) (-75) (-75) (-75) (-75) (-75) (-75) (-75) (-75) (-75) (-75) (-75) (-75) (-75) (-75) (-75) (-75)
				(-75) (-75) (-75) (-75) (-75) (-75) (-75) (-75) (-75) (-75) (-75) (-75) (-75) (-75) (-75) (-75) (-75) (-75) (-75) (-75) (-75) (-75) (-75) (-75) (-75) (-75) (-75) (-75) (-75) (-75) (-75) (-75)
				(-75) (-75) (-75) (-75) (-75) (-75) (-75) (-75) (-75) (-75) (-75) (-75) (-75) (-75) (-75) (-75) (-75) (-75) (-75) (-75) (-75) (-75) (-75) (-75) (-75) (-75) (-75) (-75) (-75) (-75) (-75) (-75)
				(-75) (-75) (-75) (-75) (-75) (-75) (-75) (-75) (-75) (-75) (-75) (-75) (-75) (-75) (-75) (-75) (-75) (-75) (-75) (-75) (-75) (-75) (-75) (-75) (-75) (-75) (-75) (-75) (-75) (-75) (-75) (-75)
				(-75) (-75) (-75) (-75) (-75) (-75) (-75) (-75) (-75) (-75) (-75) (-75) (-75) (-75) (-75) (-75) (-75) (-75) (-75) (-75) (-75) (-75) (-75) (-75) (-75) (-75) (-75) (-75) (-75) (-75) (-75) (-75)
				(-75) (-75) (-75) (-75) (-75) (-75) (-75) (-75) (-75) (-75) (-75) (-75) (-75) (-75) (-75) (-75) (-75) (-75) (-75) (-75) (-75) (-75) (-75) (-75) (-75) (-75) (-75) (-75) (-75) (-75) (-75) (-75)
				(-75) (-75) (-75) (-75) (-75) (-75) (-75) (-75) (-75) (-75) (-75) (-75) (-75) (-75) (-75) (-75) (-75) (-75) (-75) (-75) (-75) (-75) (-75) (-75) (-75) (-75) (-75) (-75) (-75) (-75) (-75) (-75)
				(-75) (-75) (-75) (-75) (-75) (-75) (-75) (-75) (-75) (-75) (-75) (-75) (-75) (-75) (-75) (-75) (-75) (-75) (-75) (-75) (-75) (-75) (-75) (-75) (-75) (-75) (-75) (-75) (-75) (-75) (-75) (-75)
				(-75) (-75) (-75) (-75) (-75) (-75) (-75) (-75) (-75) (-75) (-75) (-75) (-75) (-75) (-75) (-75) (-75) (-75) (-75) (-75) (-75) (-75) (-75) (-75) (-75) (-75) (-75) (-75) (-75) (-75) (-75) (-75)
				(-75) (-75) (-75) (-75) (-75) (-75) (-75) (-75) (-75) (-75) (-75) (-75) (-75) (-75) (-75) (-75) (-75) (-75) (-75) (-75) (-75) (-75) (-75) (-75) (-75) (-75) (-75) (-75) (-75) (-75) (-75) (-75)
				(-75) (-75) (-75) (-75) (-75) (-75) (-75) (-75) (-75) (-75) (-75) (-75) (-75) (-75) (-75) (-75) (-75) (-75) (-75) (-75) (-75) (-75) (-75) (-75) (-75) (-75) (-75) (-75) (-75) (-75) (-75) (-75)
				(-75) (-75) (-75) (-75) (-75) (-75) (-75) (-75) (-75) (-75) (-75) (-75) (-75) (-75) (-75) (-75) (-75) (-75) (-75) (-75) (-75) (-75) (-75) (-75) (-75) (-75) (-75) (-75) (-75) (-75) (-75) (-75)
				(-75) (-75) (-75) (-75) (-75) (-75) (-75) (-75) (-75) (-75) (-75) (-75) (-75) (-75) (-75) (-75) (-75) (-75) (-75) (-75) (-75) (-75) (-75) (-75) (-75) (-75) (-75) (-75) (-75) (-75) (-75) (-75)
				(-75) (-75) (-75) (-75) (-75) (-75) (-75) (-75) (-75) (-75) (-75) (-75) (-75) (-75) (-75) (-75) (-75) (-75) (-75) (-75) (-75) (-75) (-75) (-75) (-75) (-75) (-75) (-75) (-75) (-75) (-75) (-75)
				(-75) (-75) (-75) (-75) (-75) (-75) (-75) (-75) (-75) (-75) (-75) (-75) (-75) (-75) (-75) (-75) (-75) (-75) (-75) (-75) (-75) (-75) (-75) (-75) (-75) (-75) (-75) (-75) (-75) (-75) (-75) (-75)
				(-75) (-75) (-75) (-75) (-75) (-75) (-75) (-75) (-75) (-75) (-75) (-75) (-75) (-75) (-75) (-75) (-75) (-75) (-75) (-75) (-75) (-75) (-75) (-75) (-75) (-75) (-75) (-75) (-75) (-75) (-75) (-75)
				(-75) (-75) (-75) (-75) (-75) (-75) (-75) (-75) (-75) (-75) (-75) (-75) (-75) (-75) (-75) (-75) (-75) (-75) (-75) (-75) (-75) (-75) (-75) (-75) (-75) (-75) (-75) (-75) (-75) (-75) (-75) (-75)
				(-75) (-75) (-75) (-75) (-75) (-75) (-75) (-75) (-75) (-75) (-75) (-75) (-75) (-75) (-75) (-75) (-75) (-75) (-75) (-75) (-75) (-75) (-75) (-75) (-75) (-75) (-75) (-75) (-75) (-75) (-75) (-75)
				(-75) (-75) (-75) (-75) (-75) (-75) (-75) (-75) (-75) (-75) (-75) (-75) (-75) (-75) (-75) (-75) (-75) (-75) (-75) (-75) (-75) (-75) (-75) (-75) (-75) (-75) (-75) (-75) (-75) (-75) (-75) (-75)
				(-75) (-75) (-75)>;

			PS_Config_Lmt_PenTipX_FW_Raw_P = <
				570 570 570 570 570 570 570 570 570 570 570 570 570 570 570 570 570 570 570 570 570 570 570 570 570 570 570 570 570 570 570 570
				570 570 570 570 570 570 570 570 570 570 570 570 570 570 570 570 570 570 570 570 570 570 570 570 570 570 570 570 570 570 570 570
				570 570 570 570 570 570 570 570 570 570 570 570 570 570 570 570 570 570 570 570 570 570 570 570 570 570 570 570 570 570 570 570
				570 570 570 570 570 570 570 570 570 570 570 570 570 570 570 570 570 570 570 570 570 570 570 570 570 570 570 570 570 570 570 570
				570 570 570 570 570 570 570 570 570 570 570 570 570 570 570 570 570 570 570 570 570 570 570 570 570 570 570 570 570 570 570 570
				570 570 570 570 570 570 570 570 570 570 570 570 570 570 570 570 570 570 570 570 570 570 570 570 570 570 570 570 570 570 570 570>;

			PS_Config_Lmt_PenTipX_FW_Raw_N = <
				(-570) (-570) (-570) (-570) (-570) (-570) (-570) (-570) (-570) (-570) (-570) (-570) (-570) (-570) (-570) (-570) (-570) (-570) (-570) (-570) (-570) (-570) (-570) (-570) (-570) (-570) (-570) (-570) (-570) (-570) (-570) (-570)
				(-570) (-570) (-570) (-570) (-570) (-570) (-570) (-570) (-570) (-570) (-570) (-570) (-570) (-570) (-570) (-570) (-570) (-570) (-570) (-570) (-570) (-570) (-570) (-570) (-570) (-570) (-570) (-570) (-570) (-570) (-570) (-570)
				(-570) (-570) (-570) (-570) (-570) (-570) (-570) (-570) (-570) (-570) (-570) (-570) (-570) (-570) (-570) (-570) (-570) (-570) (-570) (-570) (-570) (-570) (-570) (-570) (-570) (-570) (-570) (-570) (-570) (-570) (-570) (-570)
				(-570) (-570) (-570) (-570) (-570) (-570) (-570) (-570) (-570) (-570) (-570) (-570) (-570) (-570) (-570) (-570) (-570) (-570) (-570) (-570) (-570) (-570) (-570) (-570) (-570) (-570) (-570) (-570) (-570) (-570) (-570) (-570)
				(-570) (-570) (-570) (-570) (-570) (-570) (-570) (-570) (-570) (-570) (-570) (-570) (-570) (-570) (-570) (-570) (-570) (-570) (-570) (-570) (-570) (-570) (-570) (-570) (-570) (-570) (-570) (-570) (-570) (-570) (-570) (-570)
				(-570) (-570) (-570) (-570) (-570) (-570) (-570) (-570) (-570) (-570) (-570) (-570) (-570) (-570) (-570) (-570) (-570) (-570) (-570) (-570) (-570) (-570) (-570) (-570) (-570) (-570) (-570) (-570) (-570) (-570) (-570) (-570)>;

			PS_Config_Lmt_PenTipY_FW_Raw_P = <
				570 570 570 570
				570 570 570 570
				570 570 570 570
				570 570 570 570
				570 570 570 570
				570 570 570 570
				570 570 570 570
				570 570 570 570
				570 570 570 570
				570 570 570 570
				570 570 570 570
				570 570 570 570
				570 570 570 570
				570 570 570 570
				570 570 570 570
				570 570 570 570
				570 570 570 570
				570 570 570 570
				570 570 570 570
				570 570 570 570
				570 570 570 570
				570 570 570 570
				570 570 570 570
				570 570 570 570
				570 570 570 570
				570 570 570 570
				570 570 570 570
				570 570 570 570
				570 570 570 570
				570 570 570 570
				570 570 570 570
				570 570 570 570
				570 570 570 570
				570 570 570 570
				570 570 570 570
				570 570 570 570
				570 570 570 570
				570 570 570 570
				570 570 570 570
				570 570 570 570
				570 570 570 570
				570 570 570 570
				570 570 570 570
				570 570 570 570
				570 570 570 570
				570 570 570 570
				570 570 570 570
				570 570 570 570
				570 570 570 570
				570 570 570 570>;

			PS_Config_Lmt_PenTipY_FW_Raw_N = <
				(-570) (-570) (-570) (-570)
				(-570) (-570) (-570) (-570)
				(-570) (-570) (-570) (-570)
				(-570) (-570) (-570) (-570)
				(-570) (-570) (-570) (-570)
				(-570) (-570) (-570) (-570)
				(-570) (-570) (-570) (-570)
				(-570) (-570) (-570) (-570)
				(-570) (-570) (-570) (-570)
				(-570) (-570) (-570) (-570)
				(-570) (-570) (-570) (-570)
				(-570) (-570) (-570) (-570)
				(-570) (-570) (-570) (-570)
				(-570) (-570) (-570) (-570)
				(-570) (-570) (-570) (-570)
				(-570) (-570) (-570) (-570)
				(-570) (-570) (-570) (-570)
				(-570) (-570) (-570) (-570)
				(-570) (-570) (-570) (-570)
				(-570) (-570) (-570) (-570)
				(-570) (-570) (-570) (-570)
				(-570) (-570) (-570) (-570)
				(-570) (-570) (-570) (-570)
				(-570) (-570) (-570) (-570)
				(-570) (-570) (-570) (-570)
				(-570) (-570) (-570) (-570)
				(-570) (-570) (-570) (-570)
				(-570) (-570) (-570) (-570)
				(-570) (-570) (-570) (-570)
				(-570) (-570) (-570) (-570)
				(-570) (-570) (-570) (-570)
				(-570) (-570) (-570) (-570)
				(-570) (-570) (-570) (-570)
				(-570) (-570) (-570) (-570)
				(-570) (-570) (-570) (-570)
				(-570) (-570) (-570) (-570)
				(-570) (-570) (-570) (-570)
				(-570) (-570) (-570) (-570)
				(-570) (-570) (-570) (-570)
				(-570) (-570) (-570) (-570)
				(-570) (-570) (-570) (-570)
				(-570) (-570) (-570) (-570)
				(-570) (-570) (-570) (-570)
				(-570) (-570) (-570) (-570)
				(-570) (-570) (-570) (-570)
				(-570) (-570) (-570) (-570)
				(-570) (-570) (-570) (-570)
				(-570) (-570) (-570) (-570)
				(-570) (-570) (-570) (-570)
				(-570) (-570) (-570) (-570)>;

			PS_Config_Lmt_PenRingX_FW_Raw_P = <
				570 570 570 570 570 570 570 570 570 570 570 570 570 570 570 570 570 570 570 570 570 570 570 570 570 570 570 570 570 570 570 570
				570 570 570 570 570 570 570 570 570 570 570 570 570 570 570 570 570 570 570 570 570 570 570 570 570 570 570 570 570 570 570 570
				570 570 570 570 570 570 570 570 570 570 570 570 570 570 570 570 570 570 570 570 570 570 570 570 570 570 570 570 570 570 570 570
				570 570 570 570 570 570 570 570 570 570 570 570 570 570 570 570 570 570 570 570 570 570 570 570 570 570 570 570 570 570 570 570
				570 570 570 570 570 570 570 570 570 570 570 570 570 570 570 570 570 570 570 570 570 570 570 570 570 570 570 570 570 570 570 570
				570 570 570 570 570 570 570 570 570 570 570 570 570 570 570 570 570 570 570 570 570 570 570 570 570 570 570 570 570 570 570 570>;

			PS_Config_Lmt_PenRingX_FW_Raw_N = <
				(-570) (-570) (-570) (-570) (-570) (-570) (-570) (-570) (-570) (-570) (-570) (-570) (-570) (-570) (-570) (-570) (-570) (-570) (-570) (-570) (-570) (-570) (-570) (-570) (-570) (-570) (-570) (-570) (-570) (-570) (-570) (-570)
				(-570) (-570) (-570) (-570) (-570) (-570) (-570) (-570) (-570) (-570) (-570) (-570) (-570) (-570) (-570) (-570) (-570) (-570) (-570) (-570) (-570) (-570) (-570) (-570) (-570) (-570) (-570) (-570) (-570) (-570) (-570) (-570)
				(-570) (-570) (-570) (-570) (-570) (-570) (-570) (-570) (-570) (-570) (-570) (-570) (-570) (-570) (-570) (-570) (-570) (-570) (-570) (-570) (-570) (-570) (-570) (-570) (-570) (-570) (-570) (-570) (-570) (-570) (-570) (-570)
				(-570) (-570) (-570) (-570) (-570) (-570) (-570) (-570) (-570) (-570) (-570) (-570) (-570) (-570) (-570) (-570) (-570) (-570) (-570) (-570) (-570) (-570) (-570) (-570) (-570) (-570) (-570) (-570) (-570) (-570) (-570) (-570)
				(-570) (-570) (-570) (-570) (-570) (-570) (-570) (-570) (-570) (-570) (-570) (-570) (-570) (-570) (-570) (-570) (-570) (-570) (-570) (-570) (-570) (-570) (-570) (-570) (-570) (-570) (-570) (-570) (-570) (-570) (-570) (-570)
				(-570) (-570) (-570) (-570) (-570) (-570) (-570) (-570) (-570) (-570) (-570) (-570) (-570) (-570) (-570) (-570) (-570) (-570) (-570) (-570) (-570) (-570) (-570) (-570) (-570) (-570) (-570) (-570) (-570) (-570) (-570) (-570)>;

			PS_Config_Lmt_PenRingY_FW_Raw_P = <
				570 570 570 570
				570 570 570 570
				570 570 570 570
				570 570 570 570
				570 570 570 570
				570 570 570 570
				570 570 570 570
				570 570 570 570
				570 570 570 570
				570 570 570 570
				570 570 570 570
				570 570 570 570
				570 570 570 570
				570 570 570 570
				570 570 570 570
				570 570 570 570
				570 570 570 570
				570 570 570 570
				570 570 570 570
				570 570 570 570
				570 570 570 570
				570 570 570 570
				570 570 570 570
				570 570 570 570
				570 570 570 570
				570 570 570 570
				570 570 570 570
				570 570 570 570
				570 570 570 570
				570 570 570 570
				570 570 570 570
				570 570 570 570
				570 570 570 570
				570 570 570 570
				570 570 570 570
				570 570 570 570
				570 570 570 570
				570 570 570 570
				570 570 570 570
				570 570 570 570
				570 570 570 570
				570 570 570 570
				570 570 570 570
				570 570 570 570
				570 570 570 570
				570 570 570 570
				570 570 570 570
				570 570 570 570
				570 570 570 570
				570 570 570 570>;

			PS_Config_Lmt_PenRingY_FW_Raw_N = <
				(-570) (-570) (-570) (-570)
				(-570) (-570) (-570) (-570)
				(-570) (-570) (-570) (-570)
				(-570) (-570) (-570) (-570)
				(-570) (-570) (-570) (-570)
				(-570) (-570) (-570) (-570)
				(-570) (-570) (-570) (-570)
				(-570) (-570) (-570) (-570)
				(-570) (-570) (-570) (-570)
				(-570) (-570) (-570) (-570)
				(-570) (-570) (-570) (-570)
				(-570) (-570) (-570) (-570)
				(-570) (-570) (-570) (-570)
				(-570) (-570) (-570) (-570)
				(-570) (-570) (-570) (-570)
				(-570) (-570) (-570) (-570)
				(-570) (-570) (-570) (-570)
				(-570) (-570) (-570) (-570)
				(-570) (-570) (-570) (-570)
				(-570) (-570) (-570) (-570)
				(-570) (-570) (-570) (-570)
				(-570) (-570) (-570) (-570)
				(-570) (-570) (-570) (-570)
				(-570) (-570) (-570) (-570)
				(-570) (-570) (-570) (-570)
				(-570) (-570) (-570) (-570)
				(-570) (-570) (-570) (-570)
				(-570) (-570) (-570) (-570)
				(-570) (-570) (-570) (-570)
				(-570) (-570) (-570) (-570)
				(-570) (-570) (-570) (-570)
				(-570) (-570) (-570) (-570)
				(-570) (-570) (-570) (-570)
				(-570) (-570) (-570) (-570)
				(-570) (-570) (-570) (-570)
				(-570) (-570) (-570) (-570)
				(-570) (-570) (-570) (-570)
				(-570) (-570) (-570) (-570)
				(-570) (-570) (-570) (-570)
				(-570) (-570) (-570) (-570)
				(-570) (-570) (-570) (-570)
				(-570) (-570) (-570) (-570)
				(-570) (-570) (-570) (-570)
				(-570) (-570) (-570) (-570)
				(-570) (-570) (-570) (-570)
				(-570) (-570) (-570) (-570)
				(-570) (-570) (-570) (-570)
				(-570) (-570) (-570) (-570)
				(-570) (-570) (-570) (-570)
				(-570) (-570) (-570) (-570)>;

			PS_Config_Lmt_PenTipX_FW_Diff_P = <
				870 870 870 870 870 870 870 870 870 870 870 870 870 870 870 870 870 870 870 870 870 870 870 870 870 870 870 870 870 870 870 870
				870 870 870 870 870 870 870 870 870 870 870 870 870 870 870 870 870 870 870 870 870 870 870 870 870 870 870 870 870 870 870 870
				870 870 870 870 870 870 870 870 870 870 870 870 870 870 870 870 870 870 870 870 870 870 870 870 870 870 870 870 870 870 870 870
				870 870 870 870 870 870 870 870 870 870 870 870 870 870 870 870 870 870 870 870 870 870 870 870 870 870 870 870 870 870 870 870
				870 870 870 870 870 870 870 870 870 870 870 870 870 870 870 870 870 870 870 870 870 870 870 870 870 870 870 870 870 870 870 870
				870 870 870 870 870 870 870 870 870 870 870 870 870 870 870 870 870 870 870 870 870 870 870 870 870 870 870 870 870 870 870 870>;

			PS_Config_Lmt_PenTipX_FW_Diff_N = <
				(-870) (-870) (-870) (-870) (-870) (-870) (-870) (-870) (-870) (-870) (-870) (-870) (-870) (-870) (-870) (-870) (-870) (-870) (-870) (-870) (-870) (-870) (-870) (-870) (-870) (-870) (-870) (-870) (-870) (-870) (-870) (-870)
				(-870) (-870) (-870) (-870) (-870) (-870) (-870) (-870) (-870) (-870) (-870) (-870) (-870) (-870) (-870) (-870) (-870) (-870) (-870) (-870) (-870) (-870) (-870) (-870) (-870) (-870) (-870) (-870) (-870) (-870) (-870) (-870)
				(-870) (-870) (-870) (-870) (-870) (-870) (-870) (-870) (-870) (-870) (-870) (-870) (-870) (-870) (-870) (-870) (-870) (-870) (-870) (-870) (-870) (-870) (-870) (-870) (-870) (-870) (-870) (-870) (-870) (-870) (-870) (-870)
				(-870) (-870) (-870) (-870) (-870) (-870) (-870) (-870) (-870) (-870) (-870) (-870) (-870) (-870) (-870) (-870) (-870) (-870) (-870) (-870) (-870) (-870) (-870) (-870) (-870) (-870) (-870) (-870) (-870) (-870) (-870) (-870)
				(-870) (-870) (-870) (-870) (-870) (-870) (-870) (-870) (-870) (-870) (-870) (-870) (-870) (-870) (-870) (-870) (-870) (-870) (-870) (-870) (-870) (-870) (-870) (-870) (-870) (-870) (-870) (-870) (-870) (-870) (-870) (-870)
				(-870) (-870) (-870) (-870) (-870) (-870) (-870) (-870) (-870) (-870) (-870) (-870) (-870) (-870) (-870) (-870) (-870) (-870) (-870) (-870) (-870) (-870) (-870) (-870) (-870) (-870) (-870) (-870) (-870) (-870) (-870) (-870)>;

			PS_Config_Lmt_PenTipY_FW_Diff_P = <
				870 870 870 870
				870 870 870 870
				870 870 870 870
				870 870 870 870
				870 870 870 870
				870 870 870 870
				870 870 870 870
				870 870 870 870
				870 870 870 870
				870 870 870 870
				870 870 870 870
				870 870 870 870
				870 870 870 870
				870 870 870 870
				870 870 870 870
				870 870 870 870
				870 870 870 870
				870 870 870 870
				870 870 870 870
				870 870 870 870
				870 870 870 870
				870 870 870 870
				870 870 870 870
				870 870 870 870
				870 870 870 870
				870 870 870 870
				870 870 870 870
				870 870 870 870
				870 870 870 870
				870 870 870 870
				870 870 870 870
				870 870 870 870
				870 870 870 870
				870 870 870 870
				870 870 870 870
				870 870 870 870
				870 870 870 870
				870 870 870 870
				870 870 870 870
				870 870 870 870
				870 870 870 870
				870 870 870 870
				870 870 870 870
				870 870 870 870
				870 870 870 870
				870 870 870 870
				870 870 870 870
				870 870 870 870
				870 870 870 870
				870 870 870 870>;

			PS_Config_Lmt_PenTipY_FW_Diff_N = <
				(-870) (-870) (-870) (-870)
				(-870) (-870) (-870) (-870)
				(-870) (-870) (-870) (-870)
				(-870) (-870) (-870) (-870)
				(-870) (-870) (-870) (-870)
				(-870) (-870) (-870) (-870)
				(-870) (-870) (-870) (-870)
				(-870) (-870) (-870) (-870)
				(-870) (-870) (-870) (-870)
				(-870) (-870) (-870) (-870)
				(-870) (-870) (-870) (-870)
				(-870) (-870) (-870) (-870)
				(-870) (-870) (-870) (-870)
				(-870) (-870) (-870) (-870)
				(-870) (-870) (-870) (-870)
				(-870) (-870) (-870) (-870)
				(-870) (-870) (-870) (-870)
				(-870) (-870) (-870) (-870)
				(-870) (-870) (-870) (-870)
				(-870) (-870) (-870) (-870)
				(-870) (-870) (-870) (-870)
				(-870) (-870) (-870) (-870)
				(-870) (-870) (-870) (-870)
				(-870) (-870) (-870) (-870)
				(-870) (-870) (-870) (-870)
				(-870) (-870) (-870) (-870)
				(-870) (-870) (-870) (-870)
				(-870) (-870) (-870) (-870)
				(-870) (-870) (-870) (-870)
				(-870) (-870) (-870) (-870)
				(-870) (-870) (-870) (-870)
				(-870) (-870) (-870) (-870)
				(-870) (-870) (-870) (-870)
				(-870) (-870) (-870) (-870)
				(-870) (-870) (-870) (-870)
				(-870) (-870) (-870) (-870)
				(-870) (-870) (-870) (-870)
				(-870) (-870) (-870) (-870)
				(-870) (-870) (-870) (-870)
				(-870) (-870) (-870) (-870)
				(-870) (-870) (-870) (-870)
				(-870) (-870) (-870) (-870)
				(-870) (-870) (-870) (-870)
				(-870) (-870) (-870) (-870)
				(-870) (-870) (-870) (-870)
				(-870) (-870) (-870) (-870)
				(-870) (-870) (-870) (-870)
				(-870) (-870) (-870) (-870)
				(-870) (-870) (-870) (-870)
				(-870) (-870) (-870) (-870)>;

			PS_Config_Lmt_PenRingX_FW_Diff_P = <
				870 870 870 870 870 870 870 870 870 870 870 870 870 870 870 870 870 870 870 870 870 870 870 870 870 870 870 870 870 870 870 870
				870 870 870 870 870 870 870 870 870 870 870 870 870 870 870 870 870 870 870 870 870 870 870 870 870 870 870 870 870 870 870 870
				870 870 870 870 870 870 870 870 870 870 870 870 870 870 870 870 870 870 870 870 870 870 870 870 870 870 870 870 870 870 870 870
				870 870 870 870 870 870 870 870 870 870 870 870 870 870 870 870 870 870 870 870 870 870 870 870 870 870 870 870 870 870 870 870
				870 870 870 870 870 870 870 870 870 870 870 870 870 870 870 870 870 870 870 870 870 870 870 870 870 870 870 870 870 870 870 870
				870 870 870 870 870 870 870 870 870 870 870 870 870 870 870 870 870 870 870 870 870 870 870 870 870 870 870 870 870 870 870 870>;

			PS_Config_Lmt_PenRingX_FW_Diff_N = <
				(-870) (-870) (-870) (-870) (-870) (-870) (-870) (-870) (-870) (-870) (-870) (-870) (-870) (-870) (-870) (-870) (-870) (-870) (-870) (-870) (-870) (-870) (-870) (-870) (-870) (-870) (-870) (-870) (-870) (-870) (-870) (-870)
				(-870) (-870) (-870) (-870) (-870) (-870) (-870) (-870) (-870) (-870) (-870) (-870) (-870) (-870) (-870) (-870) (-870) (-870) (-870) (-870) (-870) (-870) (-870) (-870) (-870) (-870) (-870) (-870) (-870) (-870) (-870) (-870)
				(-870) (-870) (-870) (-870) (-870) (-870) (-870) (-870) (-870) (-870) (-870) (-870) (-870) (-870) (-870) (-870) (-870) (-870) (-870) (-870) (-870) (-870) (-870) (-870) (-870) (-870) (-870) (-870) (-870) (-870) (-870) (-870)
				(-870) (-870) (-870) (-870) (-870) (-870) (-870) (-870) (-870) (-870) (-870) (-870) (-870) (-870) (-870) (-870) (-870) (-870) (-870) (-870) (-870) (-870) (-870) (-870) (-870) (-870) (-870) (-870) (-870) (-870) (-870) (-870)
				(-870) (-870) (-870) (-870) (-870) (-870) (-870) (-870) (-870) (-870) (-870) (-870) (-870) (-870) (-870) (-870) (-870) (-870) (-870) (-870) (-870) (-870) (-870) (-870) (-870) (-870) (-870) (-870) (-870) (-870) (-870) (-870)
				(-870) (-870) (-870) (-870) (-870) (-870) (-870) (-870) (-870) (-870) (-870) (-870) (-870) (-870) (-870) (-870) (-870) (-870) (-870) (-870) (-870) (-870) (-870) (-870) (-870) (-870) (-870) (-870) (-870) (-870) (-870) (-870)>;

			PS_Config_Lmt_PenRingY_FW_Diff_P = <
				870 870 870 870
				870 870 870 870
				870 870 870 870
				870 870 870 870
				870 870 870 870
				870 870 870 870
				870 870 870 870
				870 870 870 870
				870 870 870 870
				870 870 870 870
				870 870 870 870
				870 870 870 870
				870 870 870 870
				870 870 870 870
				870 870 870 870
				870 870 870 870
				870 870 870 870
				870 870 870 870
				870 870 870 870
				870 870 870 870
				870 870 870 870
				870 870 870 870
				870 870 870 870
				870 870 870 870
				870 870 870 870
				870 870 870 870
				870 870 870 870
				870 870 870 870
				870 870 870 870
				870 870 870 870
				870 870 870 870
				870 870 870 870
				870 870 870 870
				870 870 870 870
				870 870 870 870
				870 870 870 870
				870 870 870 870
				870 870 870 870
				870 870 870 870
				870 870 870 870
				870 870 870 870
				870 870 870 870
				870 870 870 870
				870 870 870 870
				870 870 870 870
				870 870 870 870
				870 870 870 870
				870 870 870 870
				870 870 870 870
				870 870 870 870>;

			PS_Config_Lmt_PenRingY_FW_Diff_N = <
				(-870) (-870) (-870) (-870)
				(-870) (-870) (-870) (-870)
				(-870) (-870) (-870) (-870)
				(-870) (-870) (-870) (-870)
				(-870) (-870) (-870) (-870)
				(-870) (-870) (-870) (-870)
				(-870) (-870) (-870) (-870)
				(-870) (-870) (-870) (-870)
				(-870) (-870) (-870) (-870)
				(-870) (-870) (-870) (-870)
				(-870) (-870) (-870) (-870)
				(-870) (-870) (-870) (-870)
				(-870) (-870) (-870) (-870)
				(-870) (-870) (-870) (-870)
				(-870) (-870) (-870) (-870)
				(-870) (-870) (-870) (-870)
				(-870) (-870) (-870) (-870)
				(-870) (-870) (-870) (-870)
				(-870) (-870) (-870) (-870)
				(-870) (-870) (-870) (-870)
				(-870) (-870) (-870) (-870)
				(-870) (-870) (-870) (-870)
				(-870) (-870) (-870) (-870)
				(-870) (-870) (-870) (-870)
				(-870) (-870) (-870) (-870)
				(-870) (-870) (-870) (-870)
				(-870) (-870) (-870) (-870)
				(-870) (-870) (-870) (-870)
				(-870) (-870) (-870) (-870)
				(-870) (-870) (-870) (-870)
				(-870) (-870) (-870) (-870)
				(-870) (-870) (-870) (-870)
				(-870) (-870) (-870) (-870)
				(-870) (-870) (-870) (-870)
				(-870) (-870) (-870) (-870)
				(-870) (-870) (-870) (-870)
				(-870) (-870) (-870) (-870)
				(-870) (-870) (-870) (-870)
				(-870) (-870) (-870) (-870)
				(-870) (-870) (-870) (-870)
				(-870) (-870) (-870) (-870)
				(-870) (-870) (-870) (-870)
				(-870) (-870) (-870) (-870)
				(-870) (-870) (-870) (-870)
				(-870) (-870) (-870) (-870)
				(-870) (-870) (-870) (-870)
				(-870) (-870) (-870) (-870)
				(-870) (-870) (-870) (-870)
				(-870) (-870) (-870) (-870)
				(-870) (-870) (-870) (-870)>;

			PS_Config_Diff_Test_Frame = <50>;
		};
	};
};
